VERSION ""

NS_ :

BS_:

BU_: Lenkmotor NJX Third_Party VCU IVT_Mod

BO_ 3221225472 VECTOR__INDEPENDENT_SIG_MSG: 0 Vector__XXX
 SG_ DMI_sdc_in_active : 0|1@1+ (1,0) [0|1] "" Vector__XXX
 SG_ DMI_sdc_out_active : 0|1@1+ (1,0) [0|1] "" Vector__XXX
 SG_ AMS_error_eio1 : 0|1@1+ (1,0) [0|1] "" Vector__XXX
 SG_ AMS_error_eio2 : 0|1@1+ (1,0) [0|1] "" Vector__XXX
 SG_ AMS_error_fan : 0|1@1+ (1,0) [0|1] "" Vector__XXX
 SG_ STW_rot_1 : 0|4@1+ (1,0) [0|15] "" Vector__XXX
 SG_ STW_rot_2 : 0|4@1+ (1,0) [0|15] "" Vector__XXX
 SG_ STW_btn_old_1 : 0|1@1+ (1,0) [0|1] "" Vector__XXX
 SG_ STW_btn_old_2 : 0|1@1+ (1,0) [0|1] "" Vector__XXX
 SG_ STW_btn_rr : 0|1@1+ (1,0) [0|1] "" Vector__XXX
 SG_ STW_btn_fr_l : 0|1@1+ (1,0) [0|1] "" Vector__XXX
 SG_ STW_btn_fl_l : 0|1@1+ (1,0) [0|1] "" Vector__XXX
 SG_ STW_btn_fl_r : 0|1@1+ (1,0) [0|1] "" Vector__XXX
 SG_ STW_btn_fr_r : 0|1@1+ (1,0) [0|1] "" Vector__XXX
 SG_ STW_btn_rl : 0|1@1+ (1,0) [0|1] "" Vector__XXX
 SG_ ISU_general_error : 0|1@1+ (1,0) [0|1] "" Vector__XXX
 SG_ ISU_mcu_error : 0|1@1+ (1,0) [0|1] "" Vector__XXX
 SG_ ISU_plaus_error : 0|1@1+ (1,0) [0|1] "" Vector__XXX
 SG_ ISU_realtime_error : 0|1@1+ (1,0) [0|1] "" Vector__XXX
 SG_ STW_CAN_Marker : 0|1@1+ (1,0) [0|1] "" Vector__XXX
 SG_ VCU_NM_all_active : 0|1@1+ (1,0) [0|1] "" Vector__XXX
 SG_ SCU_statusword : 0|16@1+ (1,0) [0|65535] "" Vector__XXX
 SG_ STW_general_error : 0|1@1+ (1,0) [0|1] "" Vector__XXX
 SG_ STW_mcu_error : 0|1@1+ (1,0) [0|1] "" Vector__XXX
 SG_ STW_plaus_error : 0|1@1+ (1,0) [0|1] "" Vector__XXX
 SG_ STW_realtime_error : 0|1@1+ (1,0) [0|1] "" Vector__XXX
 SG_ AMS_fan_pwm : 0|7@1+ (1,0) [0|127] "%" Vector__XXX
 SG_ AMS_i_battery : 0|16@1- (0.01,0) [-327.68|327.67] "A" Vector__XXX
 SG_ AMS_u_lv : 0|9@1+ (0.1,0) [0|51.1] "V" Vector__XXX
 SG_ AMS_temp_avg_stack_10 : 0|8@1+ (0.3,0) [0|76.5] "°C" Vector__XXX
 SG_ AMS_temp_avg_stack_11 : 0|8@1+ (0.3,0) [0|76.5] "°C" Vector__XXX
 SG_ AMS_temp_avg_stack_12 : 0|8@1+ (0.3,0) [0|76.5] "°C" Vector__XXX
 SG_ AMS_temp_avg_stack_9 : 0|8@1+ (0.3,0) [0|76.5] "°C" Vector__XXX
 SG_ AMS_temp_max_stack_10 : 0|8@1+ (0.3,0) [0|76.5] "°C" Vector__XXX
 SG_ AMS_temp_max_stack_11 : 0|8@1+ (0.3,0) [0|76.5] "°C" Vector__XXX
 SG_ AMS_temp_max_stack_12 : 0|8@1+ (0.3,0) [0|76.5] "°C" Vector__XXX
 SG_ AMS_temp_max_stack_9 : 0|8@1+ (0.3,0) [0|76.5] "°C" Vector__XXX
 SG_ VCU_GNSS_v_x : 0|32@1- (1,0) [-3.39999995214436E+38|3.39999995214436E+38] "m/s" Vector__XXX
 SG_ VCU_GNSS_v_y : 0|32@1- (1,0) [0|0] "m/s" Vector__XXX
 SG_ VCU_GNSS_error : 0|1@1+ (1,0) [0|1] "" Vector__XXX
 SG_ VCU_GNSS_fix : 0|1@1+ (1,0) [0|1] "" Vector__XXX
 SG_ VCU_GNSS_state : 0|2@1+ (1,0) [0|3] "" Vector__XXX
 SG_ VCU_GNSS_v_z : 0|32@1- (1,0) [0|0] "m/s" Vector__XXX
 SG_ VCU_IMU_error : 0|1@1+ (1,0) [0|1] "" Vector__XXX
 SG_ DMI_AMS_Fan_Conrtol : 0|7@1+ (1,0) [0|127] "" Vector__XXX
 SG_ SCU_steering_position : 0|32@1- (1,0) [-2147483648|2147483647] "" Vector__XXX
 SG_ NJX_CAN1_scu_ctrl_word : 0|16@1+ (1,0) [0|65535] "" Vector__XXX
 SG_ NJX_CAN1_scu_target_pos : 0|32@1- (1,0) [-2147483648|2147483647] "" Vector__XXX
 SG_ VCU_main_git_hash : 0|64@1- (1,0) [-9.22337203685478E+18|9.22337203685478E+18] "" Vector__XXX
 SG_ VCU_lib_git_hash : 0|64@1- (1,0) [-9.22337203685478E+18|9.22337203685478E+18] "" Vector__XXX

BO_ 52 SMU_BTN_sdc_reset_btn: 1 Third_Party
 SG_ SMU_BTN_rst_bt_pressed : 0|1@1+ (1,0) [0|1] "" Vector__XXX

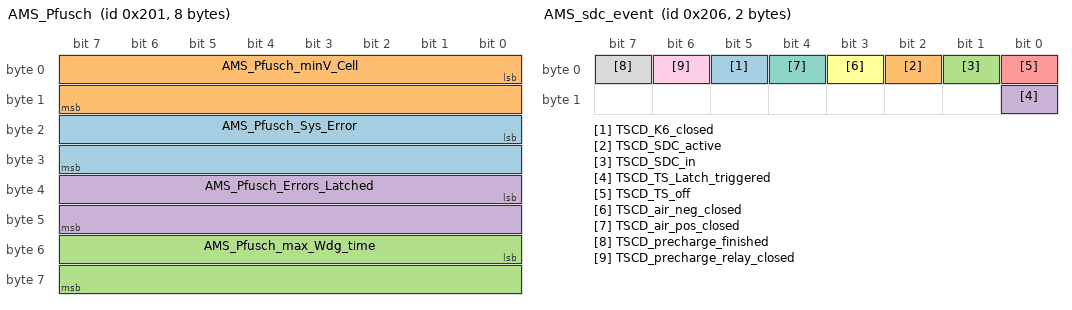
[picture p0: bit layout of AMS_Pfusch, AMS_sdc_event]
BO_ 513 AMS_Pfusch: 8 Vector__XXX
 SG_ AMS_Pfusch_Sys_Error : 16|16@1+ (1,0) [0|65535] "" Vector__XXX
 SG_ AMS_Pfusch_minV_Cell : 0|16@1+ (0.0001,0) [0|6.5535] "V" Vector__XXX
 SG_ AMS_Pfusch_max_Wdg_time : 48|16@1+ (0.001,0) [0|65.535] "s" Vector__XXX
 SG_ AMS_Pfusch_Errors_Latched : 32|16@1+ (1,0) [0|65535] "" Vector__XXX

BO_ 793 SMU_F_ASMS_state: 1 Third_Party
 SG_ SMU_F_ASMS_on : 0|1@1+ (1,0) [0|1] ""  VCU

BO_ 0 VCU_CAN1_nmt_node_control: 2 VCU
 SG_ VCU_CAN1_nmt_node_control : 0|16@1- (1,0) [0|0] ""  Third_Party

BO_ 1 CANopen_reserved_failsafe: 8 Third_Party

BO_ 48 DMI_tsa_btn: 1 Third_Party
 SG_ DMI_tsa_btn_pressed : 0|1@1+ (1,0) [0|1] ""  VCU

BO_ 50 DMI_r2d_btn: 1 Third_Party
 SG_ DMI_r2d_btn_pressed : 0|1@1+ (1,0) [0|1] ""  VCU

BO_ 518 AMS_sdc_event: 2 Third_Party
 SG_ TSCD_K6_closed : 5|1@1+ (1,0) [0|1] ""  VCU
 SG_ TSCD_SDC_active : 2|1@1+ (1,0) [0|1] ""  VCU
 SG_ TSCD_SDC_in : 1|1@1+ (1,0) [0|1] ""  VCU
 SG_ TSCD_TS_Latch_triggered : 8|1@1+ (1,0) [0|1] ""  VCU
 SG_ TSCD_TS_off : 0|1@1+ (1,0) [0|1] ""  VCU
 SG_ TSCD_air_neg_closed : 3|1@1+ (1,0) [0|1] ""  VCU
 SG_ TSCD_air_pos_closed : 4|1@1+ (1,0) [0|1] ""  VCU
 SG_ TSCD_precharge_finished : 7|1@1+ (1,0) [0|1] ""  VCU
 SG_ TSCD_precharge_relay_closed : 6|1@1+ (1,0) [0|1] ""  VCU

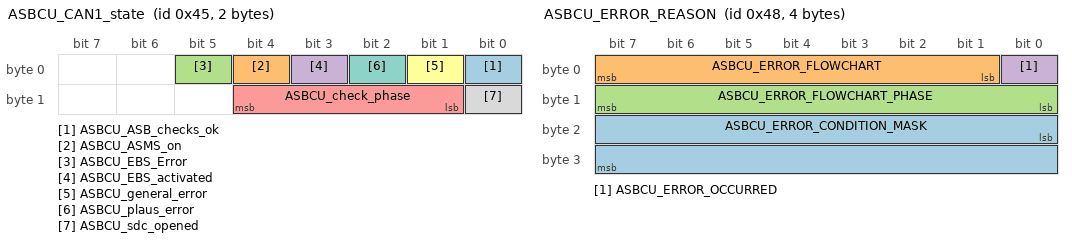
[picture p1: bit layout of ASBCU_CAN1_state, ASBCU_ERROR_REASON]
BO_ 69 ASBCU_CAN1_state: 2 Third_Party
 SG_ ASBCU_ASB_checks_ok : 0|1@1+ (1,0) [0|1] ""  VCU
 SG_ ASBCU_ASMS_on : 4|1@1+ (1,0) [0|1] ""  VCU
 SG_ ASBCU_EBS_Error : 5|1@1+ (1,0) [0|1] ""  VCU
 SG_ ASBCU_EBS_activated : 3|1@1+ (1,0) [0|1] ""  VCU
 SG_ ASBCU_check_phase : 9|4@1+ (1,0) [0|15] ""  VCU
 SG_ ASBCU_general_error : 1|1@1+ (1,0) [0|1] ""  VCU
 SG_ ASBCU_plaus_error : 2|1@1+ (1,0) [0|1] ""  VCU
 SG_ ASBCU_sdc_opened : 8|1@1+ (1,0) [0|1] ""  VCU

BO_ 70 ASBCU_CAN1_data: 2 Third_Party
 SG_ ASBCU_activated_sensor : 0|8@1+ (0.1,0) [0|25.5] ""  VCU
 SG_ ASBCU_armed_sensor : 8|8@1+ (0.1,0) [0|25.5] ""  VCU

BO_ 71 VCU_CAN1_ASBCU_Info: 8 VCU
 SG_ VCU_NJX_Mission_Status : 0|3@1+ (1,0) [0|7] ""  Third_Party

BO_ 72 ASBCU_ERROR_REASON: 4 Third_Party
 SG_ ASBCU_ERROR_CONDITION_MASK : 16|16@1+ (1,0) [0|1] ""  VCU
 SG_ ASBCU_ERROR_FLOWCHART : 1|7@1+ (1,0) [0|1] ""  VCU
 SG_ ASBCU_ERROR_FLOWCHART_PHASE : 8|8@1+ (1,0) [0|1] ""  VCU
 SG_ ASBCU_ERROR_OCCURRED : 0|1@1+ (1,0) [0|1] ""  VCU

BO_ 512 AMS_state: 6 Third_Party
 SG_ AMS_error_batt_cv_ct_init : 6|1@1+ (1,0) [0|1] ""  VCU
 SG_ AMS_error_batt_iso_meas : 4|1@1+ (1,0) [0|1] ""  VCU
 SG_ AMS_error_batt_iso_meas_monitor : 5|1@1+ (1,0) [0|1] ""  VCU
 SG_ AMS_error_batt_vit_init : 3|1@1+ (1,0) [0|1] ""  VCU
 SG_ AMS_error_bms_init_1 : 8|1@1+ (1,0) [0|1] ""  VCU
 SG_ AMS_error_bms_init_2 : 9|1@1+ (1,0) [0|1] ""  VCU
 SG_ AMS_error_bms_init_3 : 10|1@1+ (1,0) [0|1] ""  VCU
 SG_ AMS_error_can_init : 13|1@1+ (1,0) [0|1] ""  VCU
 SG_ AMS_error_current_init : 15|1@1+ (1,0) [0|1] ""  VCU
 SG_ AMS_error_cv_ct_rx_monitor : 7|1@1+ (1,0) [0|1] ""  VCU
 SG_ AMS_error_eeprom_rd : 11|1@1+ (1,0) [0|1] ""  VCU
 SG_ AMS_error_eeprom_wr : 12|1@1+ (1,0) [0|1] ""  VCU
 SG_ AMS_error_lim_cell_minmax_volt : 17|1@1+ (1,0) [0|1] ""  VCU
 SG_ AMS_error_lim_current_1_cont : 19|1@1+ (1,0) [0|1] ""  VCU
 SG_ AMS_error_lim_current_1_max : 20|1@1+ (1,0) [0|1] ""  VCU
 SG_ AMS_error_lim_current_1_pulse : 18|1@1+ (1,0) [0|1] ""  VCU
 SG_ AMS_error_lim_current_2_cont : 21|1@1+ (1,0) [0|1] ""  VCU
 SG_ AMS_error_lim_iso : 22|1@1+ (1,0) [0|1] ""  VCU
 SG_ AMS_error_lim_soc : 23|1@1+ (1,0) [0|1] ""  VCU
 SG_ AMS_error_lim_temp : 24|1@1+ (1,0) [0|1] ""  VCU
 SG_ AMS_error_lim_volt : 16|1@1+ (1,0) [0|1] ""  VCU
 SG_ AMS_error_lim_volt_ext : 25|1@1+ (1,0) [0|1] ""  VCU
 SG_ AMS_error_not_ready : 14|1@1+ (1,0) [0|1] ""  VCU
 SG_ AMS_general_error : 26|1@1+ (1,0) [0|1] ""  VCU
 SG_ AMS_mcu_error : 27|1@1+ (1,0) [0|1] ""  VCU
 SG_ AMS_plaus_error : 28|1@1+ (1,0) [0|1] ""  VCU
 SG_ AMS_realtime_error : 29|1@1+ (1,0) [0|1] ""  VCU
 SG_ AMS_soc : 32|16@1+ (0.1,0) [0|6553.5] "%"  VCU

BO_ 88 VCU_CAN1_ASI_state: 1 VCU
 SG_ ASI_Status : 0|8@1+ (1,0) [0|255] ""  Third_Party

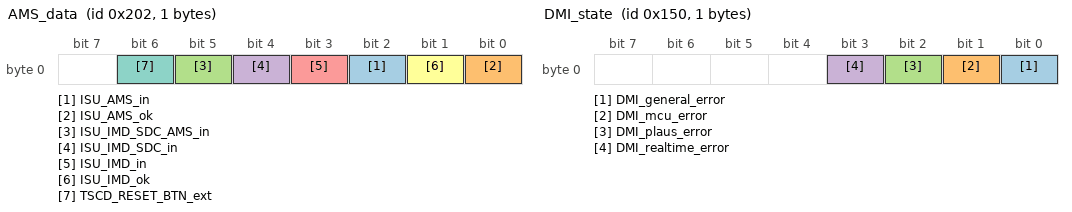
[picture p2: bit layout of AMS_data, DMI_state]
BO_ 514 AMS_data: 1 Third_Party
 SG_ ISU_AMS_in : 2|1@1+ (1,0) [0|0] ""  VCU
 SG_ ISU_AMS_ok : 0|1@1+ (1,0) [0|0] ""  VCU
 SG_ ISU_IMD_SDC_AMS_in : 5|1@1+ (1,0) [0|0] ""  VCU
 SG_ ISU_IMD_SDC_in : 4|1@1+ (1,0) [0|0] ""  VCU
 SG_ ISU_IMD_in : 3|1@1+ (1,0) [0|0] ""  VCU
 SG_ ISU_IMD_ok : 1|1@1+ (1,0) [0|0] ""  VCU
 SG_ TSCD_RESET_BTN_ext : 6|1@1+ (1,0) [0|1] ""  VCU

BO_ 127 CANopen_reserved_active: 8 Third_Party

BO_ 128 CANopen_reserved_sync: 8 Third_Party

BO_ 146 STR_emergency: 8 Third_Party
 SG_ STR_error_code : 0|16@1+ (1,0) [0|0] ""  VCU
 SG_ STR_error_register : 16|8@1+ (1,0) [0|0] ""  VCU

BO_ 322 VCU_CAN1_vehicle_state: 7 VCU
 SG_ AMS_general_error : 16|1@1+ (1,0) [0|1] ""  Third_Party
 SG_ VCU_FS_Logger_Status : 13|1@1+ (1,0) [0|1] ""  Third_Party
 SG_ VCU_LC_state : 20|2@1+ (1,0) [0|3] ""  Third_Party
 SG_ VCU_RES_status : 17|3@1+ (1,0) [0|7] ""  Third_Party
 SG_ VCU_VelEstMode : 10|2@1+ (1,0) [0|3] ""  Third_Party
 SG_ VCU_apps_error : 0|1@1+ (1,0) [0|1] ""  Third_Party
 SG_ VCU_bl_active : 14|1@1+ (1,0) [0|1] ""  Third_Party
 SG_ VCU_bpps_error : 1|1@1+ (1,0) [0|1] ""  Third_Party
 SG_ VCU_bps_error : 2|1@1+ (1,0) [0|1] ""  Third_Party
 SG_ VCU_fan_l_error : 22|1@1+ (1,0) [0|1] ""  Third_Party
 SG_ VCU_fan_r_error : 23|1@1+ (1,0) [0|1] ""  Third_Party
 SG_ VCU_fan_rl_speed : 36|6@1+ (1.5873016,0) [0|100.0000008] "%"  Third_Party
 SG_ VCU_fan_rr_speed : 42|6@1+ (1.5873016,0) [0|100.0000008] ""  Third_Party
 SG_ VCU_pump_l_error : 8|1@1+ (1,0) [0|1] ""  Third_Party
 SG_ VCU_pump_r_error : 9|1@1+ (1,0) [0|1] ""  Third_Party
 SG_ VCU_pump_rl_speed : 24|6@1+ (1.5873016,0) [0|100.0000008] ""  Third_Party
 SG_ VCU_pump_rr_speed : 30|6@1+ (1.5873016,0) [0|49.2063496] ""  Third_Party
 SG_ VCU_ready_for_rtd : 7|1@1+ (1,0) [0|1] ""  Third_Party
 SG_ VCU_ready_for_tsa : 6|1@1+ (1,0) [0|1] ""  Third_Party
 SG_ VCU_rtd : 5|1@1+ (1,0) [0|1] ""  Third_Party
 SG_ VCU_rtds_active : 15|1@1+ (1,0) [0|1] ""  Third_Party
 SG_ VCU_torque_alloc_error : 12|1@1+ (1,0) [0|1] ""  Third_Party
 SG_ VCU_tsa : 4|1@1+ (1,0) [0|1] ""  Third_Party
 SG_ VCU_vehicle_error : 3|1@1+ (1,0) [0|1] ""  Third_Party

BO_ 336 DMI_state: 1 Third_Party
 SG_ DMI_general_error : 0|1@1+ (1,0) [0|1] ""  VCU
 SG_ DMI_mcu_error : 1|1@1+ (1,0) [0|1] ""  VCU
 SG_ DMI_plaus_error : 2|1@1+ (1,0) [0|1] ""  VCU
 SG_ DMI_realtime_error : 3|1@1+ (1,0) [0|1] ""  VCU

BO_ 338 GL2010_CAN1_state: 4 Third_Party
 SG_ GL201_CAN1_dummy : 0|32@1- (1,0) [-2147483648|2147483647] ""  VCU

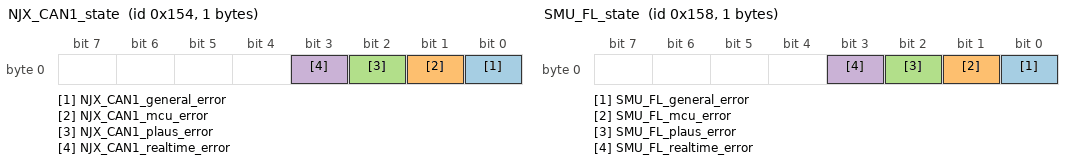
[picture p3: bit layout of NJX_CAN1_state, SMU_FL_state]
BO_ 340 NJX_CAN1_state: 1 NJX
 SG_ NJX_CAN1_general_error : 0|1@1+ (1,0) [0|1] ""  VCU
 SG_ NJX_CAN1_mcu_error : 1|1@1+ (1,0) [0|1] ""  VCU
 SG_ NJX_CAN1_plaus_error : 2|1@1+ (1,0) [0|1] ""  VCU
 SG_ NJX_CAN1_realtime_error : 3|1@1+ (1,0) [0|1] ""  VCU

BO_ 344 SMU_FL_state: 1 Third_Party
 SG_ SMU_FL_general_error : 0|1@1+ (1,0) [0|1] ""  VCU
 SG_ SMU_FL_mcu_error : 1|1@1+ (1,0) [0|1] ""  VCU
 SG_ SMU_FL_plaus_error : 2|1@1+ (1,0) [0|1] ""  VCU
 SG_ SMU_FL_realtime_error : 3|1@1+ (1,0) [0|1] ""  VCU

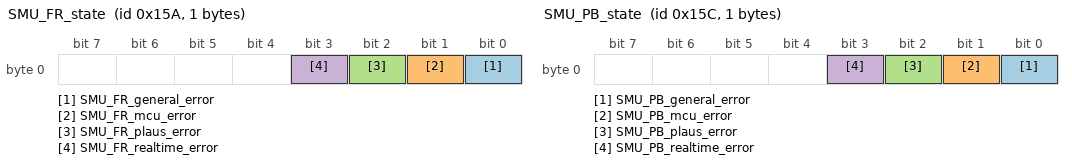
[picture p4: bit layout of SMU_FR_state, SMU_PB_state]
BO_ 346 SMU_FR_state: 1 Third_Party
 SG_ SMU_FR_general_error : 0|1@1+ (1,0) [0|1] ""  VCU
 SG_ SMU_FR_mcu_error : 1|1@1+ (1,0) [0|1] ""  VCU
 SG_ SMU_FR_plaus_error : 2|1@1+ (1,0) [0|1] ""  VCU
 SG_ SMU_FR_realtime_error : 3|1@1+ (1,0) [0|1] ""  VCU

BO_ 348 SMU_PB_state: 1 Third_Party
 SG_ SMU_PB_general_error : 0|1@1+ (1,0) [0|1] ""  VCU
 SG_ SMU_PB_mcu_error : 1|1@1+ (1,0) [0|1] ""  VCU
 SG_ SMU_PB_plaus_error : 2|1@1+ (1,0) [0|1] ""  VCU
 SG_ SMU_PB_realtime_error : 3|1@1+ (1,0) [0|1] ""  VCU

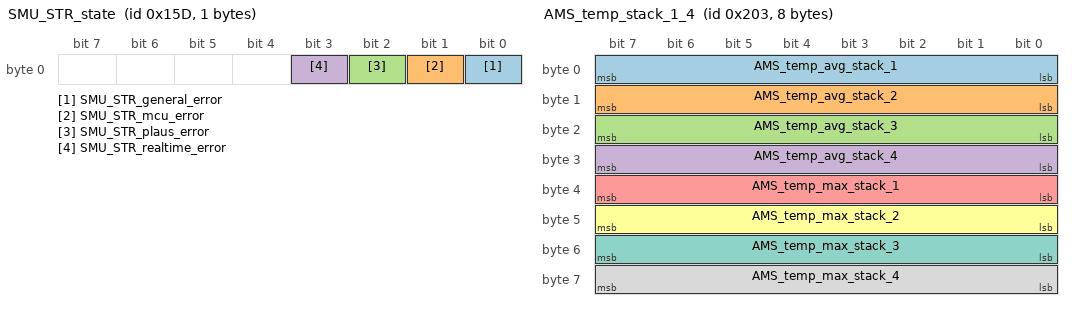
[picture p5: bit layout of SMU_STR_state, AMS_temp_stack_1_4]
BO_ 349 SMU_STR_state: 1 Third_Party
 SG_ SMU_STR_general_error : 0|1@1+ (1,0) [0|1] ""  VCU
 SG_ SMU_STR_mcu_error : 1|1@1+ (1,0) [0|1] ""  VCU
 SG_ SMU_STR_plaus_error : 2|1@1+ (1,0) [0|1] ""  VCU
 SG_ SMU_STR_realtime_error : 3|1@1+ (1,0) [0|1] ""  VCU

BO_ 352 VCU_CAN1_state: 6 VCU
 SG_ VCU_CAN1_general_error : 0|1@1+ (1,0) [0|1] ""  Third_Party
 SG_ VCU_CAN1_plaus_error : 2|1@1+ (1,0) [0|1] ""  Third_Party
 SG_ VCU_CAN1_realtime_error : 3|1@1+ (1,0) [0|1] ""  Third_Party
 SG_ VCU_diag_state : 16|8@1+ (1,0) [0|255] ""  Third_Party
 SG_ VCU_diag_state_error : 24|8@1+ (1,0) [0|255] ""  Third_Party
 SG_ VCU_ecu_error_ams : 4|1@1+ (1,0) [0|1] ""  Third_Party
 SG_ VCU_ecu_error_dmi : 5|1@1+ (1,0) [0|1] ""  Third_Party
 SG_ VCU_ecu_error_inv_f : 6|1@1+ (1,0) [0|1] ""  Third_Party
 SG_ VCU_ecu_error_inv_r : 7|1@1+ (1,0) [0|1] ""  Third_Party
 SG_ VCU_ecu_error_isu : 1|1@1+ (1,0) [0|1] ""  Third_Party
 SG_ VCU_ecu_error_scu : 8|1@1+ (1,0) [0|1] ""  Third_Party
 SG_ VCU_ecu_error_smu_btn : 9|1@1+ (1,0) [0|1] ""  Third_Party
 SG_ VCU_ecu_error_smu_fl : 10|1@1+ (1,0) [0|1] ""  Third_Party
 SG_ VCU_ecu_error_smu_fr : 11|1@1+ (1,0) [0|1] ""  Third_Party
 SG_ VCU_ecu_error_smu_pb : 12|1@1+ (1,0) [0|1] ""  Third_Party
 SG_ VCU_ecu_error_smu_rl : 13|1@1+ (1,0) [0|1] ""  Third_Party
 SG_ VCU_ecu_error_smu_rr : 14|1@1+ (1,0) [0|1] ""  Third_Party
 SG_ VCU_ecu_error_tscd : 15|1@1+ (1,0) [0|1] ""  Third_Party
 SG_ VCU_exec_time : 40|8@1+ (0.025,0) [0|6.375] "ms"  Third_Party
 SG_ VCU_watchdog_state : 32|8@1+ (1,0) [0|255] ""  Third_Party

BO_ 515 AMS_temp_stack_1_4: 8 Third_Party
 SG_ AMS_temp_avg_stack_1 : 0|8@1+ (0.3,0) [0|76.5] "°C"  VCU
 SG_ AMS_temp_avg_stack_2 : 8|8@1+ (0.3,0) [0|76.5] "°C"  VCU
 SG_ AMS_temp_avg_stack_3 : 16|8@1+ (0.3,0) [0|76.5] "°C"  VCU
 SG_ AMS_temp_avg_stack_4 : 24|8@1+ (0.3,0) [0|76.5] "°C"  VCU
 SG_ AMS_temp_max_stack_1 : 32|8@1+ (0.3,0) [0|76.5] "°C"  VCU
 SG_ AMS_temp_max_stack_2 : 40|8@1+ (0.3,0) [0|76.5] "°C"  VCU
 SG_ AMS_temp_max_stack_3 : 48|8@1+ (0.3,0) [0|76.5] "°C"  VCU
 SG_ AMS_temp_max_stack_4 : 56|8@1+ (0.3,0) [0|76.5] "°C"  VCU

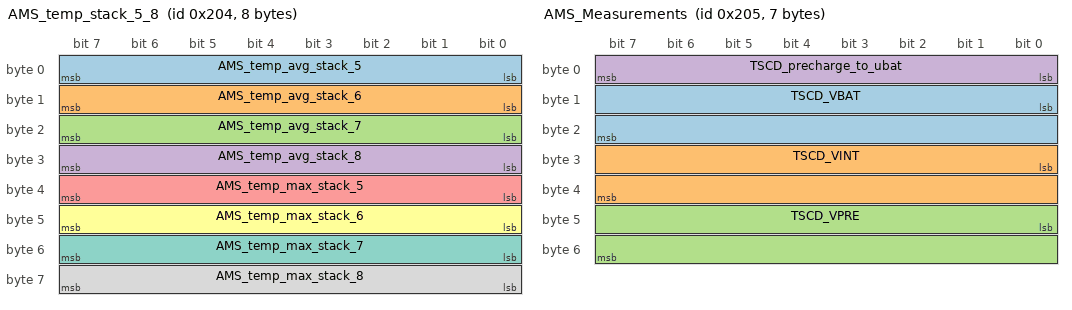
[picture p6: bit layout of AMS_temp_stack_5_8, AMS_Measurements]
BO_ 516 AMS_temp_stack_5_8: 8 Third_Party
 SG_ AMS_temp_avg_stack_5 : 0|8@1+ (0.3,0) [0|76.5] "°C"  VCU
 SG_ AMS_temp_avg_stack_6 : 8|8@1+ (0.3,0) [0|76.5] "°C"  VCU
 SG_ AMS_temp_avg_stack_7 : 16|8@1+ (0.3,0) [0|76.5] "°C"  VCU
 SG_ AMS_temp_avg_stack_8 : 24|8@1+ (0.3,0) [0|76.5] "°C"  VCU
 SG_ AMS_temp_max_stack_5 : 32|8@1+ (0.3,0) [0|76.5] "°C"  VCU
 SG_ AMS_temp_max_stack_6 : 40|8@1+ (0.3,0) [0|76.5] "°C"  VCU
 SG_ AMS_temp_max_stack_7 : 48|8@1+ (0.3,0) [0|76.5] "°C"  VCU
 SG_ AMS_temp_max_stack_8 : 56|8@1+ (0.3,0) [0|76.5] "°C"  VCU

BO_ 517 AMS_Measurements: 7 Third_Party
 SG_ TSCD_VBAT : 8|16@1+ (0.01,0) [0|655.35] "V"  VCU
 SG_ TSCD_VINT : 24|16@1+ (0.01,0) [0|655.35] "V"  VCU
 SG_ TSCD_VPRE : 40|16@1+ (0.01,0) [0|655.35] "V"  VCU
 SG_ TSCD_precharge_to_ubat : 0|8@1+ (1,0) [0|255] "%"  VCU

BO_ 530 VCU_RL_data: 2 VCU
 SG_ VCU_RL_gear_temp : 0|8@1+ (0.5,0) [0|127.5] "C"  Third_Party
 SG_ VCU_RL_motor_temp : 8|8@1+ (0.5,0) [0|127.5] "C"  Third_Party

BO_ 534 VCU_RR_data: 2 VCU
 SG_ VCU_RR_gear_temp : 0|8@1+ (0.5,0) [0|127.5] "C"  Third_Party
 SG_ VCU_RR_motor_temp : 8|8@1+ (0.5,0) [0|0] "C"  Third_Party

BO_ 600 VCU_CAN1_IMU_x: 8 VCU
 SG_ VCU_IMU_acc_x : 0|32@1- (1,0) [-3.39999995214436E+38|3.39999995214436E+38] "m/s^2"  Third_Party
 SG_ VCU_IMU_ang_x : 32|32@1- (1,0) [-3.39999995214436E+38|3.39999995214436E+38] "rad/s"  Third_Party

BO_ 601 VCU_CAN1_IMU_y: 8 VCU
 SG_ VCU_IMU_acc_y : 0|32@1- (1,0) [0|0] "m/s^2"  Third_Party
 SG_ VCU_IMU_ang_y : 32|32@1- (1,0) [0|0] "rad/s"  Third_Party

BO_ 602 VCU_CAN1_IMU_z: 8 VCU
 SG_ VCU_IMU_acc_z : 0|32@1- (1,0) [-3.39999995214436E+38|3.39999995214436E+38] "m/s^2"  Third_Party
 SG_ VCU_IMU_ang_z : 32|32@1- (1,0) [-3.39999995214436E+38|3.39999995214436E+38] "rad/s"  Third_Party

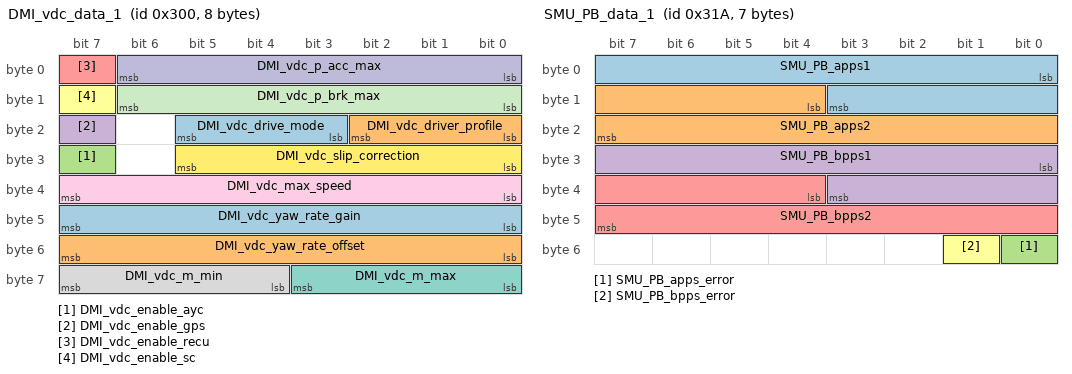
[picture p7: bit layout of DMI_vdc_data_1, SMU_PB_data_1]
BO_ 768 DMI_vdc_data_1: 8 Third_Party
 SG_ DMI_vdc_drive_mode : 19|3@1+ (1,0) [0|7] ""  VCU
 SG_ DMI_vdc_driver_profile : 16|3@1+ (1,0) [0|7] ""  VCU
 SG_ DMI_vdc_enable_ayc : 31|1@1+ (1,0) [0|1] ""  VCU
 SG_ DMI_vdc_enable_gps : 23|1@1+ (1,0) [0|1] ""  VCU
 SG_ DMI_vdc_enable_recu : 7|1@1+ (1,0) [0|1] ""  VCU
 SG_ DMI_vdc_enable_sc : 15|1@1+ (1,0) [0|1] ""  VCU
 SG_ DMI_vdc_m_max : 56|4@1+ (2.5,0) [0|37.5] "Nm"  VCU
 SG_ DMI_vdc_m_min : 60|4@1+ (2.5,-37.5) [-37.5|0] "Nm"  VCU
 SG_ DMI_vdc_max_speed : 32|8@1+ (100,0) [0|25500] "1/min"  VCU
 SG_ DMI_vdc_p_acc_max : 0|7@1+ (1000,0) [0|127000] "W"  VCU
 SG_ DMI_vdc_p_brk_max : 8|7@1+ (1000,5) [5|127005] "W"  VCU
 SG_ DMI_vdc_slip_correction : 24|6@1- (0.01,0) [-0.32|0.31] ""  VCU
 SG_ DMI_vdc_yaw_rate_gain : 40|8@1+ (0.005,0.3625) [0.3625|1.6375] ""  VCU
 SG_ DMI_vdc_yaw_rate_offset : 48|8@1- (0.005,0) [-0.64|0.635] "rad/s"  VCU

BO_ 769 DMI_vdc_data_2: 8 Third_Party
 SG_ DMI_vdc2_AMI : 0|3@1+ (1,0) [0|7] ""  VCU

BO_ 786 SMU_FL_data_1: 2 Third_Party
 SG_ SMU_FL_suspension_travel : 0|16@1- (0.01,0) [-327.68|327.67] "mm"  VCU

BO_ 788 SMU_FL_data_2: 2 Third_Party
 SG_ SMU_FL_gear_temp : 0|8@1+ (0.5,0) [0|127.5] "ï¿½C"  VCU
 SG_ SMU_FL_motor_temp : 8|8@1+ (0.5,0) [0|127.5] "ï¿½C"  VCU

BO_ 789 SMU_FL_data_3: 2 Third_Party
 SG_ SMU_FL_wheelspeed : 0|16@1- (0.1,0) [-3276.8|3276.7] "U/min"  VCU

BO_ 790 SMU_FR_data_1: 2 Third_Party
 SG_ SMU_FR_suspension_travel : 0|16@1- (0.01,0) [-327.68|327.67] "mm"  VCU

BO_ 791 SMU_FR_data_3: 2 Third_Party
 SG_ SMU_FR_wheelspeed : 0|16@1- (0.1,0) [-3276.8|3276.7] "U/min"  VCU

BO_ 792 SMU_FR_data_2: 2 Third_Party
 SG_ SMU_FR_gear_temp : 0|8@1+ (0.5,0) [0|127.5] "ï¿½C"  VCU
 SG_ SMU_FR_motor_temp : 8|8@1+ (0.5,0) [0|127.5] "ï¿½C"  VCU

BO_ 794 SMU_PB_data_1: 7 Third_Party
 SG_ SMU_PB_apps1 : 0|12@1+ (0.025,0) [0|102.375] "%"  VCU
 SG_ SMU_PB_apps2 : 12|12@1+ (0.025,0) [0|102.375] "%"  VCU
 SG_ SMU_PB_apps_error : 48|1@1+ (1,0) [0|1] ""  VCU
 SG_ SMU_PB_bpps1 : 24|12@1+ (0.025,0) [0|102.375] "%"  VCU
 SG_ SMU_PB_bpps2 : 36|12@1+ (0.025,0) [0|102.375] "%"  VCU
 SG_ SMU_PB_bpps_error : 49|1@1+ (1,0) [0|1] ""  VCU

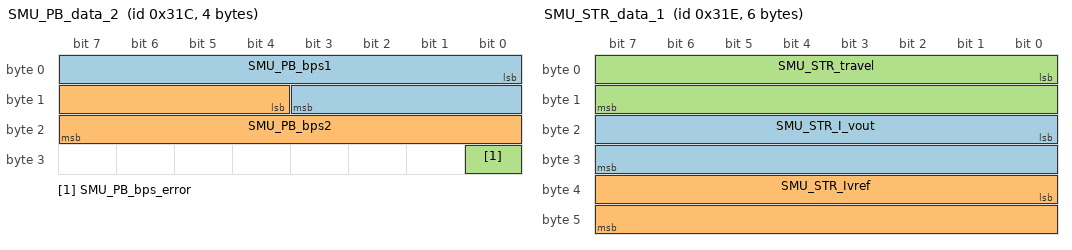
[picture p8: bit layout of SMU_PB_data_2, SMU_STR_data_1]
BO_ 796 SMU_PB_data_2: 4 Third_Party
 SG_ SMU_PB_bps1 : 0|12@1+ (0.1,0) [0|409.5] "bar"  VCU
 SG_ SMU_PB_bps2 : 12|12@1+ (0.1,0) [0|409.5] "bar"  VCU
 SG_ SMU_PB_bps_error : 24|1@1+ (1,0) [0|1] ""  VCU

BO_ 798 SMU_STR_data_1: 6 Third_Party
 SG_ SMU_STR_I_vout : 16|16@1- (0.1,0) [-3276.8|3276.7] ""  VCU
 SG_ SMU_STR_Ivref : 32|16@1- (0.1,0) [-3276.8|3276.7] ""  VCU
 SG_ SMU_STR_travel : 0|16@1- (0.01,0) [-327.68|327.67] "mm"  VCU

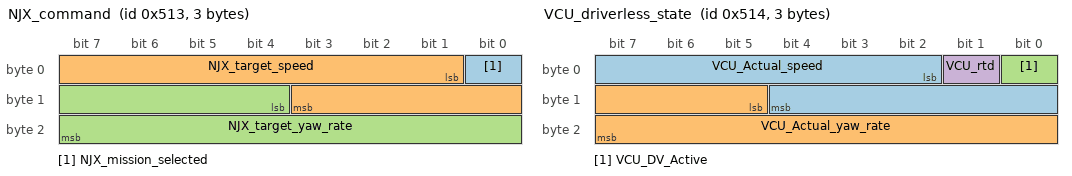
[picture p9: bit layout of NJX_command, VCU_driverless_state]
BO_ 1299 NJX_command: 3 NJX
 SG_ NJX_mission_selected : 0|1@1+ (1,0) [0|1] ""  VCU
 SG_ NJX_target_speed : 1|11@1+ (0.02,0) [0|40.94] "m/s"  VCU
 SG_ NJX_target_yaw_rate : 12|12@1- (0.002,0) [-4.096|4.094] "rad/s"  VCU

BO_ 1300 VCU_driverless_state: 3 VCU
 SG_ VCU_Actual_speed : 2|11@1+ (0.02,0) [0|40.94] "m/s"  NJX
 SG_ VCU_Actual_yaw_rate : 13|11@1- (0.004,0) [-4.096|4.092] "rad/s"  NJX
 SG_ VCU_DV_Active : 0|1@1+ (1,0) [0|1] ""  NJX
 SG_ VCU_rtd : 1|1@1+ (1,0) [0|1] ""  NJX

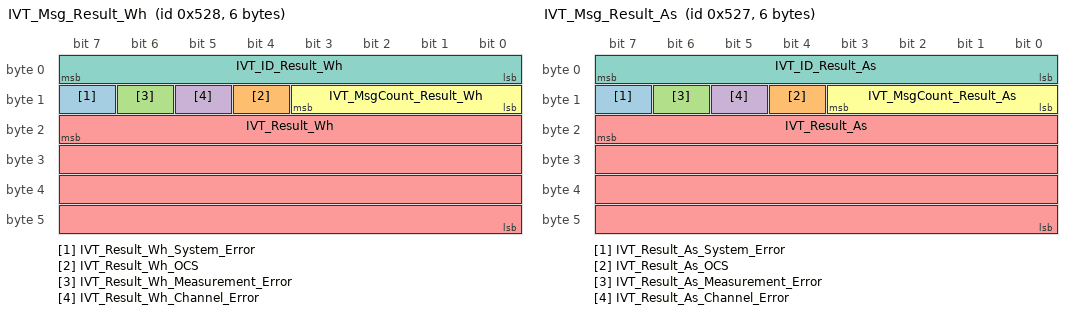
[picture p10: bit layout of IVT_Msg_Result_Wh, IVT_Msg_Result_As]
BO_ 1320 IVT_Msg_Result_Wh: 6 IVT_Mod
 SG_ IVT_Result_Wh_System_Error : 15|1@0+ (1,0) [0|0] ""  VCU
 SG_ IVT_Result_Wh_OCS : 12|1@0+ (1,0) [0|0] ""  VCU
 SG_ IVT_Result_Wh_Measurement_Error : 14|1@0+ (1,0) [0|0] ""  VCU
 SG_ IVT_Result_Wh_Channel_Error : 13|1@0+ (1,0) [0|0] ""  VCU
 SG_ IVT_Result_Wh : 23|32@0- (1,0) [-2147483648|2147483647] "Wh"  VCU
 SG_ IVT_MsgCount_Result_Wh : 11|4@0+ (1,0) [0|0] ""  VCU
 SG_ IVT_ID_Result_Wh : 7|8@0+ (1,0) [7|7] ""  VCU

BO_ 1319 IVT_Msg_Result_As: 6 IVT_Mod
 SG_ IVT_Result_As_System_Error : 15|1@0+ (1,0) [0|0] ""  VCU
 SG_ IVT_Result_As_OCS : 12|1@0+ (1,0) [0|0] ""  VCU
 SG_ IVT_Result_As_Measurement_Error : 14|1@0+ (1,0) [0|0] ""  VCU
 SG_ IVT_Result_As_Channel_Error : 13|1@0+ (1,0) [0|0] ""  VCU
 SG_ IVT_Result_As : 23|32@0- (1,0) [-21474836478|2147483647] "As"  VCU
 SG_ IVT_MsgCount_Result_As : 11|4@0+ (1,0) [0|0] ""  VCU
 SG_ IVT_ID_Result_As : 7|8@0+ (1,0) [6|6] ""  VCU

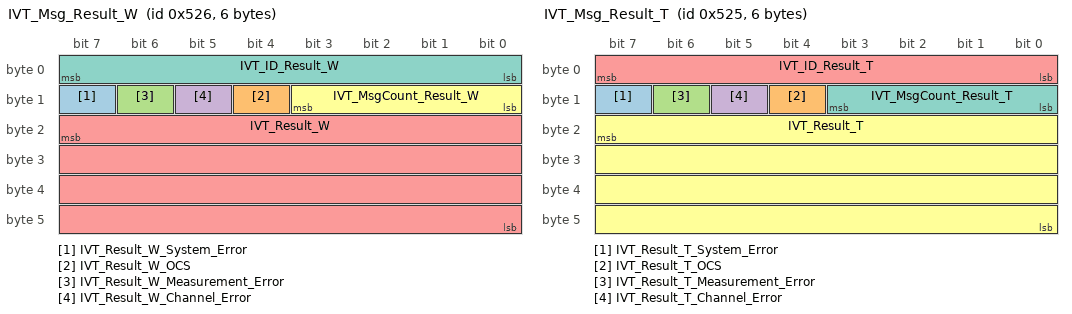
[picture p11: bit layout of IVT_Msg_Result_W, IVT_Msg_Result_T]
BO_ 1318 IVT_Msg_Result_W: 6 IVT_Mod
 SG_ IVT_Result_W_System_Error : 15|1@0+ (1,0) [0|0] ""  VCU
 SG_ IVT_Result_W_OCS : 12|1@0+ (1,0) [0|0] ""  VCU
 SG_ IVT_Result_W_Measurement_Error : 14|1@0+ (1,0) [0|0] ""  VCU
 SG_ IVT_Result_W_Channel_Error : 13|1@0+ (1,0) [0|0] ""  VCU
 SG_ IVT_Result_W : 23|32@0- (1,0) [-2147483648|2147483647] "W"  VCU
 SG_ IVT_MsgCount_Result_W : 11|4@0+ (1,0) [0|0] ""  VCU
 SG_ IVT_ID_Result_W : 7|8@0+ (1,0) [5|5] ""  VCU

BO_ 1297 IVT_Msg_Response: 8 IVT_Mod
 SG_ _B1_Trigger_spare m177 : 15|8@0+ (1,0) [0|0] "" Vector__XXX
 SG_ _B1_07_Trigger_WH m177 : 23|1@0+ (1,0) [0|0] "" Vector__XXX
 SG_ _B1_06_Trigger_As m177 : 22|1@0+ (1,0) [0|0] "" Vector__XXX
 SG_ _B1_05_Trigger_W m177 : 21|1@0+ (1,0) [0|0] "" Vector__XXX
 SG_ _B1_04_Trigger_T m177 : 20|1@0+ (1,0) [0|0] "" Vector__XXX
 SG_ _B1_03_Trigger_U3 m177 : 19|1@0+ (1,0) [0|0] "" Vector__XXX
 SG_ _B1_02_Trigger_U2 m177 : 18|1@0+ (1,0) [0|0] "" Vector__XXX
 SG_ _B1_01_Trigger_U1 m177 : 17|1@0+ (1,0) [0|0] "" Vector__XXX
 SG_ _B1_00_Trigger_I m177 : 16|1@0+ (1,0) [0|0] "" Vector__XXX
 SG_ _B2_Resp_Store_Device_SN m178 : 23|32@0+ (1,0) [0|0] "" Vector__XXX
 SG_ _FF_Wrong_Command m255 : 15|8@0+ (1,0) [0|0] "" Vector__XXX
 SG_ _BF_Restart_Alive_SN m191 : 31|32@0+ (1,0) [0|0] "" Vector__XXX
 SG_ _BF_Restart_Alive_Cmd_ID m191 : 15|16@0+ (1,0) [0|0] "" Vector__XXX
 SG_ _BA_Resp_SW_Ver_Vear m186 : 39|8@0+ (1,0) [0|0] "" Vector__XXX
 SG_ _BA_Resp_SW_Ver_Revision m186 : 31|8@0+ (1,0) [0|0] "" Vector__XXX
 SG_ _BA_Resp_SW_Ver_Month m186 : 40|8@1- (1,0) [0|0] "" Vector__XXX
 SG_ _BA_Resp_SW_Ver_Minor m186 : 23|8@0+ (1,0) [0|0] "" Vector__XXX
 SG_ _BA_Resp_SW_Ver_Internal m186 : 63|8@0+ (1,0) [0|0] "" Vector__XXX
 SG_ _BA_Resp_SW_Ver_Day m186 : 55|8@0+ (1,0) [0|0] "" Vector__XXX
 SG_ _B9_Resp_Device_Com m185 : 47|8@0+ (1,0) [0|0] "" Vector__XXX
 SG_ _B9_Resp_Device_current m185 : 23|12@0+ (1,0) [0|0] "A" Vector__XXX
 SG_ _B9_Resp_Device_TOI m185 : 39|8@0+ (1,0) [0|0] "" Vector__XXX
 SG_ _B9_Resp_Device_V_supply m185 : 55|8@0+ (1,0) [0|0] "V" Vector__XXX
 SG_ _B9_Resp_Device_Voltage_chan m185 : 27|4@0+ (1,0) [0|0] "" Vector__XXX
 SG_ _80_Resp_MeasError_Item m128 : 15|8@0+ (1,0) [0|0] "" Vector__XXX
 SG_ _80_Resp_MeasError_Count_Mask m128 : 23|16@0+ (1,0) [0|0] "" Vector__XXX
 SG_ _81_Resp_SystemError_Item m129 : 15|8@0+ (1,0) [0|0] "" Vector__XXX
 SG_ _81_Resp_SystemError_Count_Mask m129 : 23|16@0+ (1,0) [0|0] "" Vector__XXX
 SG_ _82_Resp_AllLogData_Item m130 : 15|8@0+ (1,0) [0|0] "" Vector__XXX
 SG_ _82_Resp_AllLogData_Counter m130 : 23|48@0+ (1,0) [0|0] "" Vector__XXX
 SG_ _83_Resp_LogData_Item m131 : 15|8@0+ (1,0) [0|0] "" Vector__XXX
 SG_ _83_Resp_LogData_Counter m131 : 23|48@0+ (1,0) [0|0] "" Vector__XXX
 SG_ _90_Resp_Can_ID_SN_I m144 : 31|32@0+ (1,0) [0|0] "" Vector__XXX
 SG_ _90_Resp_Can_ID_val_I m144 : 15|16@0+ (1,0) [0|0] "" Vector__XXX
 SG_ _91_Resp_Can_ID_SN_U1 m145 : 31|32@0+ (1,0) [0|0] "" Vector__XXX
 SG_ _91_Resp_Can_ID_val_U1 m145 : 15|16@0+ (1,0) [0|0] "" Vector__XXX
 SG_ _92_Resp_Can_ID_SN_U2 m146 : 31|32@0+ (1,0) [0|0] "" Vector__XXX
 SG_ _92_Resp_Can_ID_val_U2 m146 : 15|16@0+ (1,0) [0|0] "" Vector__XXX
 SG_ _93_Resp_Can_ID_SN_U3 m147 : 31|32@0+ (1,0) [0|0] "" Vector__XXX
 SG_ _93_Resp_Can_ID_val_U3 m147 : 15|16@0+ (1,0) [0|0] "" Vector__XXX
 SG_ _94_Resp_Can_ID_SN_T m148 : 31|32@0+ (1,0) [0|0] "" Vector__XXX
 SG_ _94_Resp_Can_ID_val_T m148 : 15|16@0+ (1,0) [0|0] "" Vector__XXX
 SG_ _95_Resp_Can_ID_SN_W m149 : 31|32@0+ (1,0) [0|0] "" Vector__XXX
 SG_ _95_Resp_Can_ID_val_W m149 : 15|16@0+ (1,0) [0|0] "" Vector__XXX
 SG_ _96_Resp_Can_ID_SN_As m150 : 31|32@0+ (1,0) [0|0] "" Vector__XXX
 SG_ _96_Resp_Can_ID_val_As m150 : 15|16@0+ (1,0) [0|0] "" Vector__XXX
 SG_ _97_Resp_Can_ID_SN_Wh m151 : 31|32@0+ (1,0) [0|0] "" Vector__XXX
 SG_ _97_Resp_Can_ID_val_Wh m151 : 15|16@0+ (1,0) [0|0] "" Vector__XXX
 SG_ _9D_Resp_Can_ID_SN_Command m157 : 31|32@0+ (1,0) [0|0] "" Vector__XXX
 SG_ _9D_Resp_Can_ID_val_Command m157 : 15|16@0+ (1,0) [0|0] "" Vector__XXX
 SG_ _9F_Resp_Can_ID_SN_Response m159 : 31|32@0+ (1,0) [0|0] "" Vector__XXX
 SG_ _9F_Resp_Can_ID_val_Response m159 : 15|16@0+ (1,0) [0|0] "" Vector__XXX
 SG_ _A0_Resp_CycleTime_I m160 : 23|16@0+ (1,0) [0|0] "ms" Vector__XXX
 SG_ _A0_Resp_Endianess_I m160 : 14|1@0+ (1,0) [0|0] "" Vector__XXX
 SG_ _A0_Resp_Sign_I m160 : 15|1@0+ (1,0) [0|0] "" Vector__XXX
 SG_ _A0_Resp_TriggerMode_I m160 : 9|2@0+ (1,0) [0|2] "" Vector__XXX
 SG_ _A1_Resp_CycleTime_U1 m161 : 23|16@0+ (1,0) [0|0] "ms" Vector__XXX
 SG_ _A1_Resp_Endianess_U1 m161 : 14|1@0+ (1,0) [0|0] "" Vector__XXX
 SG_ _A1_Resp_Sign_U1 m161 : 15|1@0+ (1,0) [0|0] "" Vector__XXX
 SG_ _A1_Resp_TriggerMode_U1 m161 : 9|2@0+ (1,0) [0|2] "" Vector__XXX
 SG_ _A2_Resp_CycleTime_U2 m162 : 23|16@0+ (1,0) [0|0] "ms" Vector__XXX
 SG_ _A2_Resp_Endianess_U2 m162 : 14|1@0+ (1,0) [0|0] "" Vector__XXX
 SG_ _A2_Resp_Sign_U2 m162 : 15|1@0+ (1,0) [0|0] "" Vector__XXX
 SG_ _A2_Resp_TriggerMode_U2 m162 : 9|2@0+ (1,0) [0|2] "" Vector__XXX
 SG_ _A3_Resp_CycleTime_U3 m163 : 23|16@0+ (1,0) [0|0] "ms" Vector__XXX
 SG_ _A3_Resp_Endianess_U3 m163 : 14|1@0+ (1,0) [0|0] "" Vector__XXX
 SG_ _A3_Resp_Sign_U3 m163 : 15|1@0+ (1,0) [0|0] "" Vector__XXX
 SG_ _A3_Resp_TriggerMode_U3 m163 : 9|2@0+ (1,0) [0|2] "" Vector__XXX
 SG_ _A4_Resp_CycleTime_T m164 : 23|16@0+ (1,0) [0|0] "ms" Vector__XXX
 SG_ _A4_Resp_Endianess_T m164 : 14|1@0+ (1,0) [0|0] "" Vector__XXX
 SG_ _A4_Resp_Sign_T m164 : 15|1@0+ (1,0) [0|0] "" Vector__XXX
 SG_ _A4_Resp_TriggerMode_T m164 : 9|2@0+ (1,0) [0|2] "" Vector__XXX
 SG_ _A5_Resp_CycleTime_W m165 : 23|16@0+ (1,0) [0|0] "ms" Vector__XXX
 SG_ _A5_Resp_Endianess_W m165 : 14|1@0+ (1,0) [0|0] "" Vector__XXX
 SG_ _A5_Resp_Sign_W m165 : 15|1@0+ (1,0) [0|0] "" Vector__XXX
 SG_ _A5_Resp_TriggerMode_W m165 : 9|2@0+ (1,0) [0|2] "" Vector__XXX
 SG_ _A6_Resp_CycleTime_As m166 : 23|16@0+ (1,0) [0|0] "ms" Vector__XXX
 SG_ _A6_Resp_Endianess_As m166 : 14|1@0+ (1,0) [0|0] "" Vector__XXX
 SG_ _A6_Resp_Sign_As m166 : 15|1@0+ (1,0) [0|0] "" Vector__XXX
 SG_ _A6_Resp_TriggerMode_As m166 : 9|2@0+ (1,0) [0|2] "" Vector__XXX
 SG_ _A7_Resp_CycleTime_WH m167 : 23|16@0+ (1,0) [0|0] "ms" Vector__XXX
 SG_ _A7_Resp_Endianess_WH m167 : 14|1@0+ (1,0) [0|0] "" Vector__XXX
 SG_ _A7_Resp_Sign_WH m167 : 15|1@0+ (1,0) [0|0] "" Vector__XXX
 SG_ _A7_Resp_TriggerMode_WH m167 : 9|2@0+ (1,0) [0|2] "" Vector__XXX
 SG_ _B0_Resp_Reset_Item m176 : 15|16@0+ (1,0) [0|0] "" Vector__XXX
 SG_ _B0_Resp_Reset_Device_SN m176 : 31|32@0+ (1,0) [0|0] "" Vector__XXX
 SG_ _B2_Resp_Store_dummy m178 : 15|8@0+ (1,0) [0|0] "" Vector__XXX
 SG_ _B3_Resp_Oc_Test_Time m179 : 15|16@0+ (1,0) [0|65535] "ms" Vector__XXX
 SG_ _B4_Resp_Actual_Mode m180 : 8|1@0+ (1,0) [0|0] "" Vector__XXX
 SG_ _B4_Resp_Code_Level m180 : 31|16@0+ (1,0) [0|0] "" Vector__XXX
 SG_ _B4_Resp_Startup_Mode m180 : 16|1@0+ (1,0) [0|0] "" Vector__XXX
 SG_ _B5_Resp_OC_Pos_Reset_Threshold m181 : 31|16@0- (1,0) [0|0] "" Vector__XXX
 SG_ _B5_Resp_OC_Pos_Set_Threshold m181 : 15|16@0- (1,0) [0|0] "" Vector__XXX
 SG_ _B6_Resp_OC_Neg_Reset_Threshold m182 : 31|16@0- (1,0) [0|0] "" Vector__XXX
 SG_ _B6_Resp_OC_Neg_Set_Threshold m182 : 15|16@0- (1,0) [0|0] "" Vector__XXX
 SG_ _B9_Resp_Device_type m185 : 15|8@0+ (1,0) [0|0] "" Vector__XXX
 SG_ _BA_Resp_SW_Ver_Major_HW m186 : 15|8@0+ (1,0) [0|0] "" Vector__XXX
 SG_ _BB_Resp_Serien_Nr m187 : 15|32@0+ (1,0) [0|0] "" Vector__XXX
 SG_ _BC_Resp_Art_N m188 : 15|56@0+ (1,0) [0|0] "" Vector__XXX
 SG_ IVT_ID_Response M : 7|8@0+ (1,0) [0|0] "" Vector__XXX

BO_ 1317 IVT_Msg_Result_T: 6 IVT_Mod
 SG_ IVT_Result_T_System_Error : 15|1@0+ (1,0) [0|0] ""  VCU
 SG_ IVT_Result_T_OCS : 12|1@0+ (1,0) [0|0] ""  VCU
 SG_ IVT_Result_T_Measurement_Error : 14|1@0+ (1,0) [0|0] ""  VCU
 SG_ IVT_Result_T_Channel_Error : 13|1@0+ (1,0) [0|0] ""  VCU
 SG_ IVT_ID_Result_T : 7|8@0+ (1,0) [4|4] ""  VCU
 SG_ IVT_Result_T : 23|32@0- (0.1,0) [-2147483648|2147483647] "°C"  VCU
 SG_ IVT_MsgCount_Result_T : 11|4@0+ (1,0) [0|0] ""  VCU

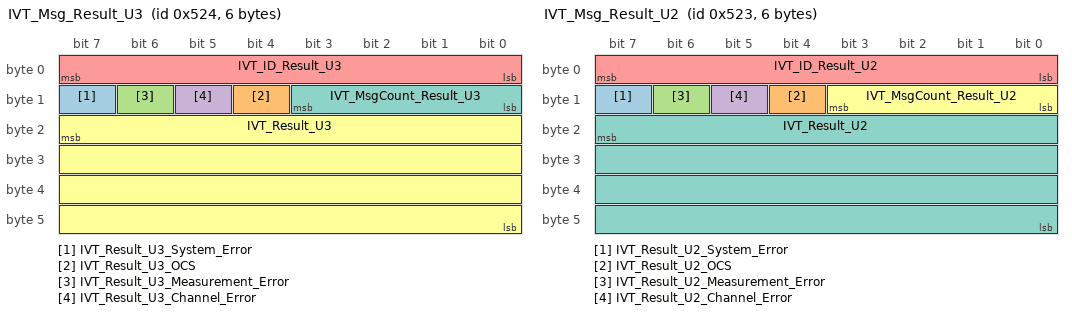
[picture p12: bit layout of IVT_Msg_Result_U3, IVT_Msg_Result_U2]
BO_ 1316 IVT_Msg_Result_U3: 6 IVT_Mod
 SG_ IVT_Result_U3_System_Error : 15|1@0+ (1,0) [0|0] ""  VCU
 SG_ IVT_Result_U3_OCS : 12|1@0+ (1,0) [0|0] ""  VCU
 SG_ IVT_Result_U3_Measurement_Error : 14|1@0+ (1,0) [0|0] ""  VCU
 SG_ IVT_Result_U3_Channel_Error : 13|1@0+ (1,0) [0|0] ""  VCU
 SG_ IVT_ID_Result_U3 : 7|8@0+ (1,0) [3|3] ""  VCU
 SG_ IVT_Result_U3 : 23|32@0- (1,0) [-2147483648|2147483647] "mV"  VCU
 SG_ IVT_MsgCount_Result_U3 : 11|4@0+ (1,0) [0|0] ""  VCU

BO_ 1315 IVT_Msg_Result_U2: 6 IVT_Mod
 SG_ IVT_Result_U2_System_Error : 15|1@0+ (1,0) [0|0] ""  VCU
 SG_ IVT_Result_U2_OCS : 12|1@0+ (1,0) [0|0] ""  VCU
 SG_ IVT_Result_U2_Measurement_Error : 14|1@0+ (1,0) [0|0] ""  VCU
 SG_ IVT_Result_U2_Channel_Error : 13|1@0+ (1,0) [0|0] ""  VCU
 SG_ IVT_ID_Result_U2 : 7|8@0+ (1,0) [2|2] ""  VCU
 SG_ IVT_MsgCount_Result_U2 : 11|4@0+ (1,0) [0|0] ""  VCU
 SG_ IVT_Result_U2 : 23|32@0- (1,0) [-2147483648|2147483647] "mV"  VCU

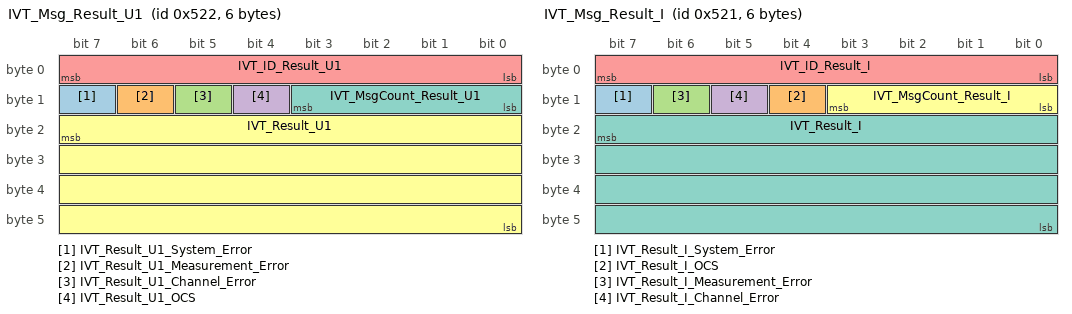
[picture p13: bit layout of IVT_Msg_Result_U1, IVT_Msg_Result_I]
BO_ 1314 IVT_Msg_Result_U1: 6 IVT_Mod
 SG_ IVT_Result_U1_System_Error : 15|1@0+ (1,0) [0|0] ""  VCU
 SG_ IVT_Result_U1_Measurement_Error : 14|1@0+ (1,0) [0|0] ""  VCU
 SG_ IVT_Result_U1_Channel_Error : 13|1@0+ (1,0) [0|0] ""  VCU
 SG_ IVT_Result_U1_OCS : 12|1@0+ (1,0) [0|0] ""  VCU
 SG_ IVT_ID_Result_U1 : 7|8@0+ (1,0) [1|1] ""  VCU
 SG_ IVT_Result_U1 : 23|32@0- (1,0) [-2147483648|2147483647] "mV"  VCU
 SG_ IVT_MsgCount_Result_U1 : 11|4@0+ (1,0) [0|0] ""  VCU

BO_ 1313 IVT_Msg_Result_I: 6 IVT_Mod
 SG_ IVT_Result_I_System_Error : 15|1@0+ (1,0) [0|0] ""  VCU
 SG_ IVT_Result_I_OCS : 12|1@0+ (1,0) [0|0] ""  VCU
 SG_ IVT_Result_I_Measurement_Error : 14|1@0+ (1,0) [0|0] ""  VCU
 SG_ IVT_Result_I_Channel_Error : 13|1@0+ (1,0) [0|0] ""  VCU
 SG_ IVT_ID_Result_I : 7|8@0+ (1,0) [0|0] ""  VCU
 SG_ IVT_MsgCount_Result_I : 11|4@0+ (1,0) [0|0] ""  VCU
 SG_ IVT_Result_I : 23|32@0- (1,0) [-2147483648|2147483647] "mA"  VCU

BO_ 1041 IVT_Msg_Cmd: 8 VCU
 SG_ _31_01_Trigger_U1 m49 : 17|1@0+ (1,0) [0|0] "" Vector__XXX
 SG_ _31_07_Trigger_WH m49 : 23|1@0+ (1,0) [0|0] "" Vector__XXX
 SG_ _31_06_Trigger_As m49 : 22|1@0+ (1,0) [0|0] "" Vector__XXX
 SG_ _31_05_Trigger_W m49 : 21|1@0+ (1,0) [0|0] "" Vector__XXX
 SG_ _31_04_Trigger_T m49 : 20|1@0+ (1,0) [0|0] "" Vector__XXX
 SG_ _31_03_Trigger_U3 m49 : 19|1@0+ (1,0) [0|0] "" Vector__XXX
 SG_ _31_Trigger_spare m49 : 15|8@0+ (1,0) [0|0] "" Vector__XXX
 SG_ _31_02_Trigger_U2 m49 : 18|1@0+ (1,0) [0|0] "" Vector__XXX
 SG_ _10_Set_Can_ID_SN_I m16 : 31|32@0+ (1,0) [0|0] "" Vector__XXX
 SG_ _10_Set_Can_ID_val_I m16 : 15|16@0+ (1,0) [0|2047] ""  IVT_Mod
 SG_ _11_Set_Can_ID_SN_U1 m17 : 31|32@0+ (1,0) [0|0] "" Vector__XXX
 SG_ _11_Set_Can_ID_val_U1 m17 : 15|16@0+ (1,0) [0|2047] "" Vector__XXX
 SG_ _12_Set_Can_ID_SN_U2 m18 : 31|32@0+ (1,0) [0|0] "" Vector__XXX
 SG_ _12_Set_Can_ID_val_U2 m18 : 15|16@0+ (1,0) [0|2047] "" Vector__XXX
 SG_ _13_Set_Can_ID_SN_U3 m19 : 31|32@0+ (1,0) [0|0] "" Vector__XXX
 SG_ _13_Set_Can_ID_val_U3 m19 : 15|16@0+ (1,0) [0|2047] "" Vector__XXX
 SG_ _14_Set_Can_ID_SN_T m20 : 31|32@0+ (1,0) [0|0] "" Vector__XXX
 SG_ _14_Set_Can_ID_val_T m20 : 15|16@0+ (1,0) [0|2047] "" Vector__XXX
 SG_ _15_Set_Can_ID_SN_W m21 : 31|32@0+ (1,0) [0|0] "" Vector__XXX
 SG_ _15_Set_Can_ID_val_W m21 : 15|16@0+ (1,0) [0|2047] "" Vector__XXX
 SG_ _16_Set_Can_ID_SN_As m22 : 31|32@0+ (1,0) [0|0] "" Vector__XXX
 SG_ _16_Set_Can_ID_val_As m22 : 15|16@0+ (1,0) [0|2047] "" Vector__XXX
 SG_ _17_Set_Can_ID_SN_Wh m23 : 31|32@0+ (1,0) [0|0] "" Vector__XXX
 SG_ _17_Set_Can_ID_val_Wh m23 : 15|16@0+ (1,0) [0|2047] "" Vector__XXX
 SG_ _1D_Set_Can_ID_SN_Command m29 : 31|32@0+ (1,0) [0|0] "" Vector__XXX
 SG_ _1D_Set_Can_ID_val_Command m29 : 15|16@0+ (1,0) [0|2047] "" Vector__XXX
 SG_ _1F_Set_Can_ID_SN_Response m31 : 31|32@0+ (1,0) [0|0] "" Vector__XXX
 SG_ _1F_Set_Can_ID_val_Response m31 : 15|16@0+ (1,0) [0|2047] "" Vector__XXX
 SG_ _20_Conf_CycleTime_I m32 : 23|16@0+ (1,0) [0|0] "ms" Vector__XXX
 SG_ _20_Conf_Endianess_I m32 : 14|1@0+ (1,0) [0|0] "" Vector__XXX
 SG_ _20_Conf_Sign_I m32 : 15|1@0+ (1,0) [0|0] "" Vector__XXX
 SG_ _20_Conf_TriggerMode_I m32 : 9|2@0+ (1,0) [0|2] "" Vector__XXX
 SG_ _21_Conf_CycleTime_U1 m33 : 23|16@0+ (1,0) [0|0] "ms" Vector__XXX
 SG_ _21_Conf_Endianess_U1 m33 : 14|1@0+ (1,0) [0|0] "" Vector__XXX
 SG_ _21_Conf_Sign_U1 m33 : 15|1@0+ (1,0) [0|0] "" Vector__XXX
 SG_ _21_Conf_TriggerMode_U1 m33 : 9|2@0+ (1,0) [0|2] "" Vector__XXX
 SG_ _22_Conf_CycleTime_U2 m34 : 23|16@0+ (1,0) [0|0] "ms" Vector__XXX
 SG_ _22_Conf_Endianess_U2 m34 : 14|1@0+ (1,0) [0|0] "" Vector__XXX
 SG_ _22_Conf_Sign_U2 m34 : 15|1@0+ (1,0) [0|0] "" Vector__XXX
 SG_ _22_Conf_TriggerMode_U2 m34 : 9|2@0+ (1,0) [0|2] "" Vector__XXX
 SG_ _23_Conf_CycleTime_U3 m35 : 23|16@0+ (1,0) [0|0] "ms" Vector__XXX
 SG_ _23_Conf_Endianess_U3 m35 : 14|1@0+ (1,0) [0|0] "" Vector__XXX
 SG_ _23_Conf_Sign_U3 m35 : 15|1@0+ (1,0) [0|0] "" Vector__XXX
 SG_ _23_Conf_TriggerMode_U3 m35 : 9|2@0+ (1,0) [0|2] "" Vector__XXX
 SG_ _24_Conf_CycleTime_T m36 : 23|16@0+ (1,0) [0|0] "ms" Vector__XXX
 SG_ _24_Conf_Endianess_T m36 : 14|1@0+ (1,0) [0|0] "" Vector__XXX
 SG_ _24_Conf_Sign_T m36 : 15|1@0+ (1,0) [0|0] "" Vector__XXX
 SG_ _24_Conf_TriggerMode_T m36 : 9|2@0+ (1,0) [0|2] "" Vector__XXX
 SG_ _25_Conf_CycleTime_W m37 : 23|16@0+ (1,0) [0|0] "ms" Vector__XXX
 SG_ _25_Conf_Endianess_W m37 : 14|1@0+ (1,0) [0|0] "" Vector__XXX
 SG_ _25_Conf_Sign_W m37 : 15|1@0+ (1,0) [0|0] "" Vector__XXX
 SG_ _25_Conf_TriggerMode_W m37 : 9|2@0+ (1,0) [0|2] "" Vector__XXX
 SG_ _26_Conf_CycleTime_As m38 : 23|16@0+ (1,0) [0|0] "ms" Vector__XXX
 SG_ _26_Conf_Endianess_As m38 : 14|1@0+ (1,0) [0|0] "" Vector__XXX
 SG_ _26_Conf_Sign_As m38 : 15|1@0+ (1,0) [0|0] "" Vector__XXX
 SG_ _26_Conf_TriggerMode_As m38 : 9|2@0+ (1,0) [0|2] "" Vector__XXX
 SG_ _27_Conf_CycleTime_WH m39 : 23|16@0+ (1,0) [0|0] "ms" Vector__XXX
 SG_ _27_Conf_Endianess_WH m39 : 14|1@0+ (1,0) [0|0] "" Vector__XXX
 SG_ _27_Conf_Sign_WH m39 : 15|1@0+ (1,0) [0|0] "" Vector__XXX
 SG_ _27_Conf_TriggerMode_WH m39 : 9|2@0+ (1,0) [0|2] "" Vector__XXX
 SG_ _30_Reset_Item m48 : 15|16@0+ (1,0) [0|0] "" Vector__XXX
 SG_ _30_Reset_Device_SN m48 : 31|32@0+ (1,0) [0|0] "" Vector__XXX
 SG_ _31_00_Trigger_I m49 : 16|1@0+ (1,0) [0|0] "" Vector__XXX
 SG_ _32_Store_dummy m50 : 15|8@0+ (1,0) [0|0] "" Vector__XXX
 SG_ _33_Oc_Test_Time m51 : 15|16@0+ (1,0) [0|65535] "ms" Vector__XXX
 SG_ _34_Actual_Mode m52 : 8|1@0+ (1,0) [0|0] "" Vector__XXX
 SG_ _34_Code_Level m52 : 31|16@0+ (1,0) [0|0] "" Vector__XXX
 SG_ _34_Startup_Mode m52 : 16|1@0+ (1,0) [0|0] "" Vector__XXX
 SG_ _35_OC_Pos_Reset_Threshold m53 : 31|16@0- (1,0) [0|0] "A" Vector__XXX
 SG_ _35_OC_Pos_Set_Threshold m53 : 15|16@0- (1,0) [0|0] "A" Vector__XXX
 SG_ _36_OC_Neg_Reset_Threshold m54 : 31|16@0- (1,0) [0|0] "A" Vector__XXX
 SG_ _36_OC_Neg_Set_Threshold m54 : 15|16@0- (1,0) [0|0] "A" Vector__XXX
 SG_ _3A_RESTART_to_Bitrate m58 : 15|8@0+ (1,0) [0|0] "" Vector__XXX
 SG_ _3D_Restart_Default_Dummy m61 : 15|8@0+ (1,0) [0|0] "" Vector__XXX
 SG_ _3F_Restart_Dummy m63 : 15|8@0+ (1,0) [0|0] "" Vector__XXX
 SG_ _40_Get_MeasError_Item m64 : 15|8@0+ (1,0) [0|0] "" Vector__XXX
 SG_ _41_Get_SystemError_Item m65 : 15|8@0+ (1,0) [0|0] "" Vector__XXX
 SG_ _42_Get_AllLogData_Item m66 : 15|8@0+ (1,0) [0|0] "" Vector__XXX
 SG_ _43_Get_LogData_Item m67 : 15|8@0+ (1,0) [0|0] "" Vector__XXX
 SG_ _50_Get_Can_ID_SN_I m80 : 31|32@0+ (1,0) [0|0] "" Vector__XXX
 SG_ _51_Get_Can_ID_SN_U1 m81 : 31|32@0+ (1,0) [0|0] "" Vector__XXX
 SG_ _52_Get_Can_ID_SN_U2 m82 : 31|32@0+ (1,0) [0|0] "" Vector__XXX
 SG_ _53_Get_Can_ID_SN_U3 m83 : 31|32@0+ (1,0) [0|0] "" Vector__XXX
 SG_ _54_Get_Can_ID_SN_T m84 : 31|32@0+ (1,0) [0|0] "" Vector__XXX
 SG_ _55_Get_Can_ID_SN_W m85 : 31|32@0+ (1,0) [0|0] "" Vector__XXX
 SG_ _56_Get_Can_ID_SN_As m86 : 31|32@0+ (1,0) [0|0] "" Vector__XXX
 SG_ _57_Get_Can_ID_SN_Wh m87 : 31|32@0+ (1,0) [0|0] "" Vector__XXX
 SG_ _5D_Get_Can_ID_SN_Command m93 : 31|32@0+ (1,0) [0|0] "" Vector__XXX
 SG_ _5F_Get_Can_ID_SN_Response m95 : 31|32@0+ (1,0) [0|0] "" Vector__XXX
 SG_ _60_Get_Result_dummy_I m96 : 15|8@0+ (1,0) [0|0] "" Vector__XXX
 SG_ _61_Get_Result_dummy_U1 m97 : 15|8@0+ (1,0) [0|0] "" Vector__XXX
 SG_ _62_Get_Result_dummy_U2 m98 : 15|8@0+ (1,0) [0|0] "" Vector__XXX
 SG_ _63_Get_Result_dummy_U3 m99 : 15|8@0+ (1,0) [0|0] "" Vector__XXX
 SG_ _64_Get_Result_dummy_T m100 : 15|8@0+ (1,0) [0|0] "" Vector__XXX
 SG_ _65_Get_Result_dummy_W m101 : 15|8@0+ (1,0) [0|0] "" Vector__XXX
 SG_ _66_Get_Result_dummy_As m102 : 15|8@0+ (1,0) [0|0] "" Vector__XXX
 SG_ _67_Get_Result_dummy_Wh m103 : 15|8@0+ (1,0) [0|0] "" Vector__XXX
 SG_ _73_Get_OC_Test_dummy m115 : 15|8@0+ (1,0) [0|0] "" Vector__XXX
 SG_ _74_Get_Mode_dummy m116 : 15|8@0+ (1,0) [0|0] "" Vector__XXX
 SG_ _75_Get_OC_Pos_dummy m117 : 15|8@0+ (1,0) [0|0] "" Vector__XXX
 SG_ _76_Get_OC_Neg_dummy m118 : 15|8@0+ (1,0) [0|0] "" Vector__XXX
 SG_ _79_Get_Device_Id_dummy m121 : 15|8@0+ (1,0) [0|0] "" Vector__XXX
 SG_ _7A_Get_SW_Version_dummy m122 : 15|8@0+ (1,0) [0|0] "" Vector__XXX
 SG_ _7B_Get_Serien_Nr_dummy m123 : 15|8@0+ (1,0) [0|0] "" Vector__XXX
 SG_ _7C_Get_Art_Nr_dummy m124 : 15|8@0+ (1,0) [0|0] "" Vector__XXX
 SG_ IVT_ID_Cmd M : 7|8@0+ (1,0) [0|0] ""  IVT_Mod

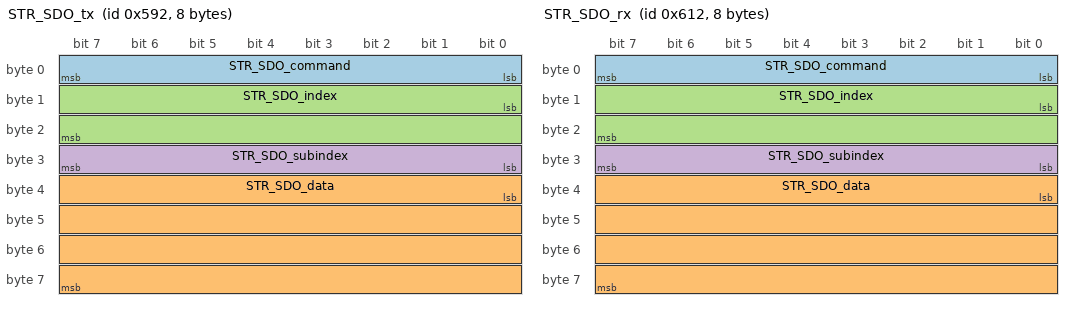
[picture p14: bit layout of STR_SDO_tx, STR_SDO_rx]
BO_ 1426 STR_SDO_tx: 8 Third_Party
 SG_ STR_SDO_command : 0|8@1+ (1,0) [0|0] ""  VCU
 SG_ STR_SDO_data : 32|32@1- (1,0) [-2147483648|2147483647] ""  VCU
 SG_ STR_SDO_index : 8|16@1+ (1,0) [0|32767] ""  VCU
 SG_ STR_SDO_subindex : 24|8@1+ (1,0) [0|255] ""  VCU

BO_ 1554 STR_SDO_rx: 8 VCU
 SG_ STR_SDO_command : 0|8@1+ (1,0) [0|0] ""  Third_Party
 SG_ STR_SDO_data : 32|32@1- (1,0) [-2147483648|2147483647] ""  Third_Party
 SG_ STR_SDO_index : 8|16@1+ (1,0) [0|32767] ""  Third_Party
 SG_ STR_SDO_subindex : 24|8@1+ (1,0) [0|255] ""  Third_Party

BO_ 1664 CAN_Flash_RX: 8 Third_Party

BO_ 1665 CAN_Flash_SMU_RL_TX: 8 Third_Party

BO_ 1666 CAN_Flash_SMU_RR_TX: 8 Third_Party

BO_ 1667 CAN_Flash_SMU_F_TX: 8 Third_Party

BO_ 1668 CAN_Flash_SMU_PB_TX: 8 Third_Party

BO_ 1670 CAN_Flash_ASI_TX: 8 VCU

BO_ 1672 CAN_Flash_DMI_TX: 8 Third_Party

BO_ 1673 CAN_Flash_SMU_AD_TX: 8 Third_Party

BO_ 1675 CAN_Flash_SMU_TESTBENCH_TX: 8 Third_Party

BO_ 1676 CAN_Flash_DCDC_ACTIVATION: 8 Third_Party

BO_ 1679 CAN_Flash_SMU_test: 8 VCU

BO_ 1760 CANopen_reserved_dynamic_sdo: 8 Third_Party

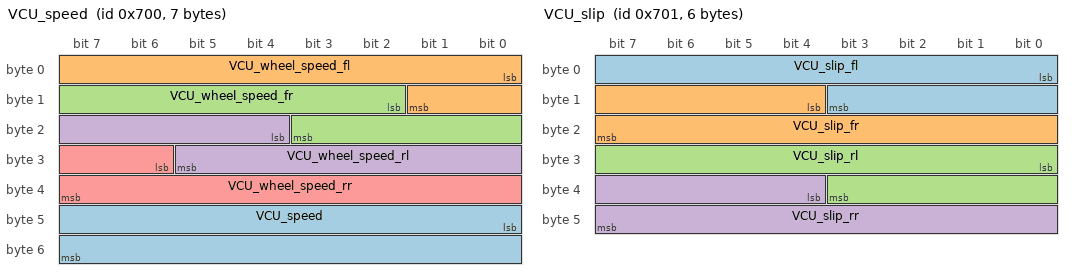
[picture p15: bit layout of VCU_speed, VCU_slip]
BO_ 1792 VCU_speed: 7 VCU
 SG_ VCU_speed : 40|16@1- (0.005,0) [-163.84|163.835] "m/s"  Third_Party
 SG_ VCU_wheel_speed_fl : 0|10@1- (0.2,50) [-52.4|152.2] "m/s"  Third_Party
 SG_ VCU_wheel_speed_fr : 10|10@1- (0.2,50) [-52.4|152.2] "m/s"  Third_Party
 SG_ VCU_wheel_speed_rl : 20|10@1- (0.2,50) [-52.4|152.2] "m/s"  Third_Party
 SG_ VCU_wheel_speed_rr : 30|10@1- (0.2,50) [-52.4|152.2] "m/s"  Third_Party

BO_ 1793 VCU_slip: 6 VCU
 SG_ VCU_slip_fl : 0|12@1- (0.001,0) [-2.048|2.047] "%"  Third_Party
 SG_ VCU_slip_fr : 12|12@1- (0.001,0) [-2.048|2.047] "%"  Third_Party
 SG_ VCU_slip_rl : 24|12@1- (0.001,0) [-2.048|2.047] "%"  Third_Party
 SG_ VCU_slip_rr : 36|12@1- (0.001,0) [-2.048|2.047] "%"  Third_Party

BO_ 1794 VCU_inverter_state: 7 VCU
 SG_ VCU_INV_fault : 40|1@1+ (1,0) [0|1] ""  Third_Party
 SG_ VCU_INV_fault_reaction_active : 41|1@1+ (1,0) [0|1] ""  Third_Party
 SG_ VCU_INV_field_weakening_active : 42|1@1+ (1,0) [0|1] ""  Third_Party
 SG_ VCU_INV_not_ready_to_switch_on : 43|1@1+ (1,0) [0|1] ""  Third_Party
 SG_ VCU_INV_operation_enabled : 44|1@1+ (1,0) [0|1] ""  Third_Party
 SG_ VCU_INV_quick_stop_active : 45|1@1+ (1,0) [0|1] ""  Third_Party
 SG_ VCU_INV_ready_to_switch_on : 46|1@1+ (1,0) [0|1] ""  Third_Party
 SG_ VCU_INV_switch_on_disabled : 47|1@1+ (1,0) [0|1] ""  Third_Party
 SG_ VCU_INV_switched_on : 48|1@1+ (1,0) [0|1] ""  Third_Party
 SG_ VCU_INV_voltage_enabled : 49|1@1+ (1,0) [0|1] ""  Third_Party
 SG_ VCU_inv_fl_active : 0|1@1+ (1,0) [0|1] ""  Third_Party
 SG_ VCU_inv_fl_error : 1|1@1+ (1,0) [0|1] ""  Third_Party
 SG_ VCU_inv_fl_state : 8|8@1+ (1,0) [0|255] ""  Third_Party
 SG_ VCU_inv_fr_active : 2|1@1+ (1,0) [0|1] ""  Third_Party
 SG_ VCU_inv_fr_error : 3|1@1+ (1,0) [0|1] ""  Third_Party
 SG_ VCU_inv_fr_state : 16|8@1+ (1,0) [0|255] ""  Third_Party
 SG_ VCU_inv_rl_active : 4|1@1+ (1,0) [0|1] ""  Third_Party
 SG_ VCU_inv_rl_error : 5|1@1+ (1,0) [0|1] ""  Third_Party
 SG_ VCU_inv_rl_state : 24|8@1+ (1,0) [0|255] ""  Third_Party
 SG_ VCU_inv_rr_active : 6|1@1+ (1,0) [0|1] ""  Third_Party
 SG_ VCU_inv_rr_error : 7|1@1+ (1,0) [0|1] ""  Third_Party
 SG_ VCU_inv_rr_state : 32|8@1+ (1,0) [0|255] ""  Third_Party

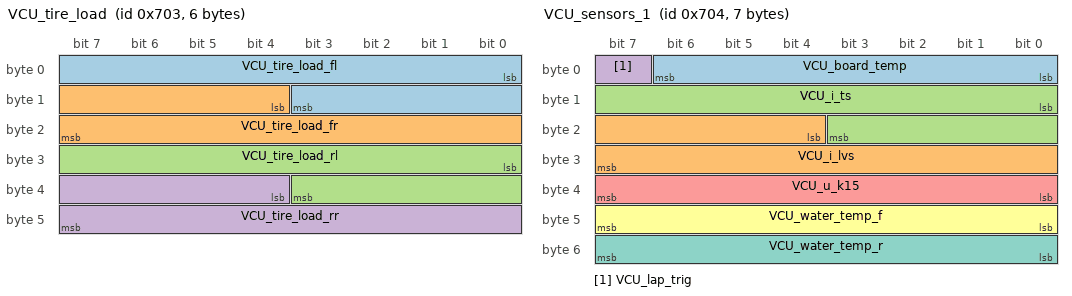
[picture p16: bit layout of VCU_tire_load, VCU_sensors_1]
BO_ 1795 VCU_tire_load: 6 VCU
 SG_ VCU_tire_load_fl : 0|12@1- (1,1000) [-1048|3047] "N"  Third_Party
 SG_ VCU_tire_load_fr : 12|12@1- (1,1000) [-1048|3047] "N"  Third_Party
 SG_ VCU_tire_load_rl : 24|12@1- (1,1000) [-1048|3047] "N"  Third_Party
 SG_ VCU_tire_load_rr : 36|12@1- (1,1000) [-1048|3047] "N"  Third_Party

BO_ 1796 VCU_sensors_1: 7 VCU
 SG_ VCU_board_temp : 0|7@1- (1,50) [-14|113] "ï¿½C"  Third_Party
 SG_ VCU_i_lvs : 20|12@1- (0.037,0) [-75.776|75.739] "A"  Third_Party
 SG_ VCU_i_ts : 8|12@1- (0.042,0) [-86.016|85.974] "A"  Third_Party
 SG_ VCU_lap_trig : 7|1@1+ (1,0) [0|1] ""  Third_Party
 SG_ VCU_u_k15 : 32|8@1+ (0.12,0) [0|30.6] "V"  Third_Party
 SG_ VCU_water_temp_f : 40|8@1+ (0.4,0) [0|102] "ï¿½C"  Third_Party
 SG_ VCU_water_temp_r : 48|8@1+ (0.4,0) [0|102] "ï¿½C"  Third_Party

BO_ 1797 VCU_sensors_2: 2 VCU
 SG_ VCU_flow_f : 0|8@1+ (0.1,0) [0|25.5] "l/min"  Third_Party
 SG_ VCU_flow_r : 8|8@1+ (0.1,0) [0|25.5] "l/min"  Third_Party

BO_ 1798 VCU_odometer: 8 VCU
 SG_ VCU_odometer : 0|16@1+ (5,0) [0|327675] "m"  Third_Party

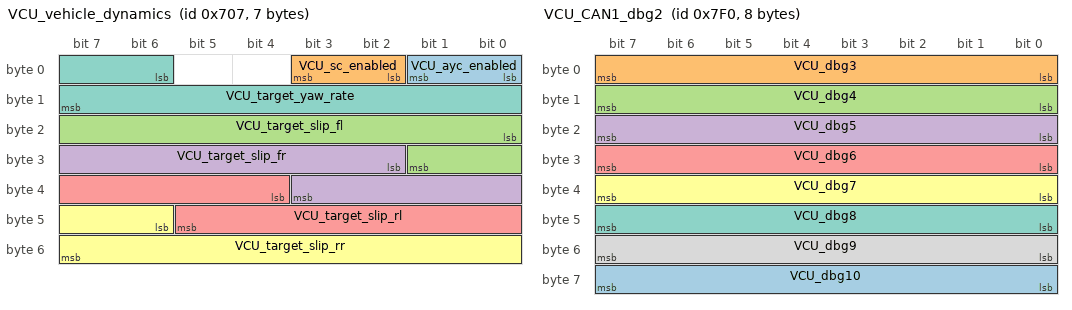
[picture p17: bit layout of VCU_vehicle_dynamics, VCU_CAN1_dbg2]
BO_ 1799 VCU_vehicle_dynamics: 7 VCU
 SG_ VCU_ayc_enabled : 0|2@1+ (1,0) [0|3] ""  Third_Party
 SG_ VCU_sc_enabled : 2|2@1+ (1,0) [0|3] ""  Third_Party
 SG_ VCU_target_slip_fl : 16|10@1- (0.004,0) [-2.048|2.044] ""  Third_Party
 SG_ VCU_target_slip_fr : 26|10@1- (0.004,0) [-2.048|2.044] ""  Third_Party
 SG_ VCU_target_slip_rl : 36|10@1- (0.004,0) [-2.048|2.044] ""  Third_Party
 SG_ VCU_target_slip_rr : 46|10@1- (0.004,0) [-2.048|2.044] ""  Third_Party
 SG_ VCU_target_yaw_rate : 6|10@1- (0.01,0) [-5.12|5.11] "rad/s"  Third_Party

BO_ 1800 VCU_lap_time: 3 VCU
 SG_ VCU_lap_complete : 16|1@1+ (1,0) [0|1] ""  Third_Party
 SG_ VCU_lap_time : 0|16@1+ (0.01,0) [0|655.35] "s"  Third_Party

BO_ 1809 VCU_dbc_git_hash: 8 VCU
 SG_ VCU_dbc_git_hash : 0|64@1- (1,0) [-9.22337203685478E+18|9.22337203685478E+18] ""  Third_Party

BO_ 1810 STR_reserved_NMT: 8 Third_Party

BO_ 2020 CANopen_reserved_LSS_tx: 8 Third_Party

BO_ 2021 CANopen_reserved_LSS_rx: 8 Third_Party

BO_ 2032 VCU_CAN1_dbg2: 8 VCU
 SG_ VCU_dbg10 : 56|8@1+ (1,0) [0|255] ""  Third_Party
 SG_ VCU_dbg3 : 0|8@1- (1,0) [-128|127] ""  Third_Party
 SG_ VCU_dbg4 : 8|8@1+ (1,0) [0|255] ""  Third_Party
 SG_ VCU_dbg5 : 16|8@1- (1,0) [-128|127] ""  Third_Party
 SG_ VCU_dbg6 : 24|8@1+ (1,0) [0|255] ""  Third_Party
 SG_ VCU_dbg7 : 32|8@1+ (1,0) [0|255] ""  Third_Party
 SG_ VCU_dbg8 : 40|8@1+ (1,0) [0|255] ""  Third_Party
 SG_ VCU_dbg9 : 48|8@1+ (1,0) [0|255] ""  Third_Party

BO_ 2047 VCU_CAN1_dbg: 8 VCU
 SG_ VCU_dbg1 : 0|32@1- (1,0) [-3.39999995214436E+38|3.39999995214436E+38] ""  Third_Party
 SG_ VCU_dbg2 : 32|32@1- (1,0) [-3.39999995214436E+38|3.39999995214436E+38] ""  Third_Party

CM_ BO_ 3221225472 "This is a message for not used signals, created by Vector CANdb++ DBC OLE DB Provider.";
CM_ SG_ 352 VCU_diag_state_error "Should have a value table, but the table is very long and i dont really have the time to do it now. well se how important this signal really is...";
CM_ SG_ 352 VCU_exec_time "Execution time of the VCU Software in ms. should never be above 5ms, so a range from 0-6ms is probably enough";
BA_DEF_  "DBName" STRING ;
BA_DEF_ BO_  "GenMsgCycleTime" INT 0 0;
BA_DEF_ BO_  "GenMsgSendType" ENUM  "Cyclic","OnEvent";
BA_DEF_ SG_  "GenSigSendType" ENUM  "NoSigSendType";
BA_DEF_ SG_  "GenSigStartValue" INT 0 0;
BA_DEF_ SG_  "SPN" INT 0 524287;
BA_DEF_DEF_  "DBName" "";
BA_DEF_DEF_  "GenMsgCycleTime" 0;
BA_DEF_DEF_  "GenMsgSendType" "";
BA_DEF_DEF_  "GenSigSendType" "";
BA_DEF_DEF_  "GenSigStartValue" 0;
BA_DEF_DEF_  "SPN" 0;
BA_ "DBName" "CAN1";
BA_ "GenMsgSendType" BO_ 52 1;
BA_ "GenMsgSendType" BO_ 0 1;
BA_ "GenMsgSendType" BO_ 1 1;
BA_ "GenMsgSendType" BO_ 48 1;
BA_ "GenMsgSendType" BO_ 50 1;
BA_ "GenMsgSendType" BO_ 518 1;
BA_ "GenMsgSendType" BO_ 69 1;
BA_ "GenMsgSendType" BO_ 70 1;
BA_ "GenMsgSendType" BO_ 71 1;
BA_ "GenMsgSendType" BO_ 72 1;
BA_ "GenMsgSendType" BO_ 512 1;
BA_ "GenMsgSendType" BO_ 88 0;
BA_ "GenMsgCycleTime" BO_ 88 100;
BA_ "GenMsgSendType" BO_ 514 1;
BA_ "GenMsgSendType" BO_ 127 1;
BA_ "GenMsgSendType" BO_ 128 1;
BA_ "GenMsgSendType" BO_ 146 1;
BA_ "GenMsgSendType" BO_ 322 1;
BA_ "GenMsgSendType" BO_ 336 1;
BA_ "GenMsgSendType" BO_ 338 1;
BA_ "GenMsgSendType" BO_ 340 1;
BA_ "GenMsgSendType" BO_ 344 1;
BA_ "GenMsgSendType" BO_ 346 1;
BA_ "GenMsgSendType" BO_ 348 1;
BA_ "GenMsgSendType" BO_ 349 1;
BA_ "GenMsgSendType" BO_ 352 1;
BA_ "GenMsgSendType" BO_ 515 1;
BA_ "GenMsgSendType" BO_ 516 1;
BA_ "GenMsgSendType" BO_ 517 1;
BA_ "GenMsgSendType" BO_ 530 1;
BA_ "GenMsgSendType" BO_ 534 1;
BA_ "GenMsgSendType" BO_ 600 1;
BA_ "GenMsgSendType" BO_ 601 1;
BA_ "GenMsgSendType" BO_ 602 1;
BA_ "GenMsgSendType" BO_ 768 0;
BA_ "GenMsgCycleTime" BO_ 768 100;
BA_ "GenMsgSendType" BO_ 769 1;
BA_ "GenMsgSendType" BO_ 786 1;
BA_ "GenMsgSendType" BO_ 788 1;
BA_ "GenMsgSendType" BO_ 789 1;
BA_ "GenMsgSendType" BO_ 790 1;
BA_ "GenMsgSendType" BO_ 791 1;
BA_ "GenMsgSendType" BO_ 792 1;
BA_ "GenMsgSendType" BO_ 794 1;
BA_ "GenMsgSendType" BO_ 796 1;
BA_ "GenMsgSendType" BO_ 798 1;
BA_ "GenMsgSendType" BO_ 1299 1;
BA_ "GenMsgSendType" BO_ 1300 1;
BA_ "GenMsgSendType" BO_ 1426 0;
BA_ "GenMsgSendType" BO_ 1554 0;
BA_ "GenMsgSendType" BO_ 1664 1;
BA_ "GenMsgSendType" BO_ 1665 1;
BA_ "GenMsgSendType" BO_ 1666 1;
BA_ "GenMsgSendType" BO_ 1667 1;
BA_ "GenMsgSendType" BO_ 1668 1;
BA_ "GenMsgSendType" BO_ 1670 0;
BA_ "GenMsgCycleTime" BO_ 1670 100;
BA_ "GenMsgSendType" BO_ 1672 1;
BA_ "GenMsgSendType" BO_ 1673 1;
BA_ "GenMsgSendType" BO_ 1675 1;
BA_ "GenMsgSendType" BO_ 1676 1;
BA_ "GenMsgSendType" BO_ 1679 0;
BA_ "GenMsgCycleTime" BO_ 1679 100;
BA_ "GenMsgSendType" BO_ 1760 1;
BA_ "GenMsgSendType" BO_ 1792 1;
BA_ "GenMsgSendType" BO_ 1793 1;
BA_ "GenMsgSendType" BO_ 1794 1;
BA_ "GenMsgSendType" BO_ 1795 1;
BA_ "GenMsgSendType" BO_ 1796 1;
BA_ "GenMsgSendType" BO_ 1797 1;
BA_ "GenMsgSendType" BO_ 1798 1;
BA_ "GenMsgSendType" BO_ 1799 1;
BA_ "GenMsgSendType" BO_ 1800 1;
BA_ "GenMsgSendType" BO_ 1809 1;
BA_ "GenMsgSendType" BO_ 1810 1;
BA_ "GenMsgSendType" BO_ 2020 1;
BA_ "GenMsgSendType" BO_ 2021 1;
BA_ "GenMsgSendType" BO_ 2032 1;
BA_ "GenMsgSendType" BO_ 2047 1;
BA_ "GenSigSendType" SG_ 1320 IVT_Result_Wh 7;
BA_ "GenSigSendType" SG_ 1320 IVT_ID_Result_Wh 7;
BA_ "GenSigStartValue" SG_ 1320 IVT_ID_Result_Wh 7;
BA_ "GenSigSendType" SG_ 1319 IVT_ID_Result_As 7;
BA_ "GenSigStartValue" SG_ 1319 IVT_ID_Result_As 6;
BA_ "GenSigSendType" SG_ 1318 IVT_ID_Result_W 7;
BA_ "GenSigStartValue" SG_ 1318 IVT_ID_Result_W 5;
BA_ "GenSigStartValue" SG_ 1297 _A0_Resp_TriggerMode_I 2;
BA_ "GenSigStartValue" SG_ 1297 _A4_Resp_TriggerMode_T 2;
BA_ "GenSigStartValue" SG_ 1297 _A5_Resp_TriggerMode_W 2;
BA_ "GenSigStartValue" SG_ 1297 _A6_Resp_TriggerMode_As 2;
BA_ "GenSigStartValue" SG_ 1297 _A7_Resp_TriggerMode_WH 2;
BA_ "GenSigSendType" SG_ 1317 IVT_ID_Result_T 7;
BA_ "GenSigStartValue" SG_ 1317 IVT_ID_Result_T 4;
BA_ "GenSigSendType" SG_ 1316 IVT_ID_Result_U3 7;
BA_ "GenSigStartValue" SG_ 1316 IVT_ID_Result_U3 3;
BA_ "GenSigSendType" SG_ 1315 IVT_ID_Result_U2 7;
BA_ "GenSigStartValue" SG_ 1315 IVT_ID_Result_U2 2;
BA_ "GenSigSendType" SG_ 1314 IVT_ID_Result_U1 7;
BA_ "GenSigStartValue" SG_ 1314 IVT_ID_Result_U1 1;
BA_ "GenSigSendType" SG_ 1314 IVT_Result_U1 7;
BA_ "GenSigSendType" SG_ 1313 IVT_ID_Result_I 7;
BA_ "GenSigSendType" SG_ 1313 IVT_Result_I 7;
VAL_ 1320 IVT_ID_Result_Wh 7 "Vt_Result_Wh" ;
VAL_ 1319 IVT_ID_Result_As 6 "Vt_Result_As" ;
VAL_ 1318 IVT_ID_Result_W 5 "Vt_Result_W" ;
VAL_ 1297 _B9_Resp_Device_Com 2 "CAN 2 - not terminated" 1 "CAN 1 - terminated" 0 "none" ;
VAL_ 1297 _B9_Resp_Device_current 2500 "2500 A" 1000 "1000 A" 500 "500 A" 300 "300 A" 100 "100 A" ;
VAL_ 1297 _B9_Resp_Device_TOI 3 "I" ;
VAL_ 1297 _B9_Resp_Device_V_supply 1 "12 / 24 V nominal supply voltage" ;
VAL_ 1297 _B9_Resp_Device_Voltage_chan 3 "3 Channels" 0 "0 Channels" ;
VAL_ 1297 _80_Resp_MeasError_Item 15 "Resp error calibration data" 14 "Resp error ntc-I OpenCirc" 13 "Resp error ntc-h OpenCirc" 12 "Resp error meas U3 OpenCirc" 11 "Resp error meas U2 OpenCirc" 10 "Resp error meas U1 OpenCirc" 9 "Resp error meas I1 OpenCirc" 8 "Resp  error therm EMF correction" 7 "Resp error cur meas implausible" 6 "Resp error Vref" 5 "Resp error Underflow ADC ch 2" 4 "Resp error Overflow ADC ch 2" 3 "Resp error Underflow ADC ch 1" 2 "Reso error Overflow ADC ch 1" 1 "Resp error ADC interrupt" 0 "Resonse all meas errors" ;
VAL_ 1297 _81_Resp_SystemError_Item 16 "Resp error Reset EMC" 15 "Resp error Reset Watchdog" 14 "Resp error Reset illegal opcode" 13 "Resp error ADC Clock" 12 "Resp error eeprom r/w" 11 "Resp error Overcurrent detection" 10 "Resp error Configuration" 9 "Resp error System Init" 8 "Resp error System Clock" 7 "Resp error Power failure" 6 "Resp error Undertemp" 5 "Resp error Overtemp" 4 "Resp error CAN bus transmit Data" 3 "Resp error CAN bus receive Data" 2 "Resp error Parameter CRC" 1 "Resp error code CRC" 0 "Resonse all SystemErrors" ;
VAL_ 1297 _82_Resp_AllLogData_Item 42 "Resp temp minimum" 41 "Resp temp maxmimum" 40 "Resp U3 minimum" 39 "Resp U3 maximum" 38 "Resp U2 minimum" 37 "Resp U2 maxmimum" 36 "Resp U1 minimum" 35 "Resp U1 maximum" 34 "Resp current minimum" 33 "Resp current maximum" 28 "Resp oc negative activated" 27 "Resp oc positive activated" 26 "Resp run temp out spec limits" 25 "Resp run temp in spec limits" 24 "Resp run volt 3 out spec limits" 23 "Resp run volt 3 in spec limits" 22 "Resp run volt 2 out spec limits" 21 "Resp run volt 2 in spec limits" 20 "Resp run volt 1 out spec limits" 19 "Resp run volt 1 in spec limits" 18 "Resp run cur out spec limits" 17 "Resp run cur in spec limits" 16 "Resp run overall" 6 "Resp energy counter discharging" 5 "Resp energy counter charging" 4 "Resp energy counter overall" 3 "Resp Ah counter discharging" 2 "Resp Ah counter charging" 1 "Resp Ah counter overall" 0 "Response on Overall Logdata" ;
VAL_ 1297 _83_Resp_LogData_Item 42 "Resp temp minimum" 41 "Resp temp maxmimum" 40 "Resp U3 minimum" 39 "Resp U3 maximum" 38 "Resp U2 minimum" 37 "Resp U2 maxmimum" 36 "Resp U1 minimum" 35 "Resp U1 maximum" 34 "Resp current minimum" 33 "Resp current maximum" 28 "Resp oc negative activated" 27 "Resp oc positive activated" 26 "Resp run temp out spec limits" 25 "Resp run temp in spec limits" 24 "Resp run volt 3 out spec limits" 23 "Resp run volt 3 in spec limits" 22 "Resp run volt 2 out spec limits" 21 "Resp run volt 2 in spec limits" 20 "Resp run volt 1 out spec limits" 19 "Resp run volt 1 in spec limits" 18 "Resp run cur out spec limits" 17 "Resp run cur in spec limits" 16 "Resp run overall" 6 "Resp energy counter discharging" 5 "Resp energy counter charging" 4 "Resp energy counter overall" 3 "Resp Ah counter discharging" 2 "Resp Ah counter charging" 1 "Resp Ah counter overall" 0 "Response all Logdata SinceReset" ;
VAL_ 1297 _A0_Resp_TriggerMode_I 2 "CYCLIC" 1 "TRIGGERED" 0 "DISABLED" ;
VAL_ 1297 _A1_Resp_TriggerMode_U1 2 "CYCLIC" 1 "TRIGGERED" 0 "DISABLED" ;
VAL_ 1297 _A2_Resp_TriggerMode_U2 2 "CYCLIC" 1 "TRIGGERED" 0 "DISABLED" ;
VAL_ 1297 _A3_Resp_TriggerMode_U3 2 "CYCLIC" 1 "TRIGGERED" 0 "DISABLED" ;
VAL_ 1297 _A4_Resp_TriggerMode_T 2 "CYCLIC" 1 "TRIGGERED" 0 "DISABLED" ;
VAL_ 1297 _A5_Resp_TriggerMode_W 2 "CYCLIC" 1 "TRIGGERED" 0 "DISABLED" ;
VAL_ 1297 _A6_Resp_TriggerMode_As 2 "CYCLIC" 1 "TRIGGERED" 0 "DISABLED" ;
VAL_ 1297 _A7_Resp_TriggerMode_WH 2 "CYCLIC" 1 "TRIGGERED" 0 "DISABLED" ;
VAL_ 1297 _B0_Resp_Reset_Item 554 "Reset temp minimum" 553 "Reset temp maximum" 552 "Reset U3 minimum" 551 "Reset U3 maximum" 550 "Reset U2 minimum" 549 "Reset U2 maximum" 548 "Reset U1 minimum" 547 "Reset U1 maximum" 546 "Reset Current minimum" 545 "Reset Current maximum" 540 "Reset Run overcur neg activated" 539 "Reset Run overcur pos activated" 538 "Reset Run temp out spec limits" 537 "Reset Run temp in spec limits" 536 "Reset Run volt 3 out spec limits" 535 "Reset Run volt 3 in spec limits" 534 "Reset Run volt 2 out spec limits" 533 "Reset Run volt 2 in spec limits" 532 "Reset Run volt 1 out spec limits" 531 "Reset Run volt 1 in spec limits" 530 "Reset Run cur out spec limits" 529 "Reset Run cur in spec limits" 528 "Reset Runtime overall" 518 "Reset Energy counter discharging" 517 "Reset Energy counter charging" 516 "Reset Energy counter overall" 515 "Reset Ah counter discharging" 514 "Reset Ah counter charging" 513 "Reset Ah counter overall" 512 "Reset all Logdata Since Reset" 272 "Reset Reset EMC" 271 "Reset Reset Watchdog" 270 "Reset illegal opcode" 269 "Reset ADC Clock" 268 "Reset eeprom r/w" 267 "Reset overcurrent detection" 266 "Reset configuration" 265 "Reset system init" 264 "Reset system clock" 263 "Reset power failure" 262 "Reset undertemp" 261 "Reset overtemp" 260 "Reset CAN bus transmit Data" 259 "Reset CAN bus receive Data" 258 "Reset Parameter CRC" 257 "Reset Code CRC" 256 "Reset all System errors" 15 "Reset calibration data " 14 "Reset ntc-I OpenCircuit" 13 "Reset ntc-h OpenCircuit" 12 "Reset voltage measU3 OpenCircuit" 11 "Reset voltage measU2 OpenCircuit" 10 "Reset voltage measU1 OpenCircuit" 9 "Reset current measI1 OpenCircuit" 8 "Reset thermal EMF correction" 7 "Reset error current implausible" 6 "Reset error Vref" 5 "Reset error Underflow ADC ch2" 4 "Reset error Overflow ADC ch2" 3 "Reset error Underflow ADC ch1" 2 "Reset error Overflow ADC ch1" 1 "Reset error ADC interrupt" 0 "Reset all measurement errors" ;
VAL_ 1297 _B4_Resp_Actual_Mode 1 "RUN" 0 "STOP" ;
VAL_ 1297 _B4_Resp_Startup_Mode 1 "Run" 0 "Stop" ;
VAL_ 1297 _B9_Resp_Device_type 2 "IVT-S" 1 "IVT-Mod" ;
VAL_ 1297 IVT_ID_Response 255 "Resp_Cmd_Wrong_Command" 191 "Resp_Get_Set_ALIVE" 188 "Resp_Get_Set_ArtNr" 187 "Resp_Get_Set_Serialnumber" 186 "Resp_Get_Set_SW_VERSION" 185 "Resp_Get_Set_DEVICE_ID" 182 "Resp_Get_Set_THRESHOLD_NEG" 181 "Resp_Get_Set_THRESHOLD_POS" 180 "Resp_Get_Set_MODE" 179 "Resp_Get_Set_OC_TEST_TIME" 178 "Resp_Get_Set_STORE" 177 "Resp_Get_Set_TRIGGER" 176 "Resp_Get_Set_Reset_Error_Logdata" 167 "Resp_Config_Result_Wh" 166 "Resp_Config_Result_As" 165 "Resp_Config_Result_W" 164 "Resp_Config_Result_T" 163 "Resp_Config_Result_U3" 162 "Resp_Config_Result_U2" 161 "Resp_Config_Result_U1" 160 "Resp_Config_Result_I" 159 "Resp_CAN_ID_Response" 157 "Resp_CAN_ID_Command" 151 "Resp_CAN_ID_Res_Wh" 150 "Resp_CAN_ID_Res_As" 149 "Resp_CAN_ID_Res_W" 144 "Resp_CAN_ID_Res_I" 148 "Resp_CAN_ID_Res_T" 147 "Resp_CAN_ID_Res_U3" 146 "Resp_CAN_ID_Res_U2" 145 "Resp_CAN_ID_Res_U1" 131 "Resp_Error_Log_Logdata_Since_Res" 130 "Resp_Error_Log_Overall_Logdata" 129 "Resp_Error_Log_System_Error" 128 "Resp_Error_Log_Measurement_Error" ;
VAL_ 1317 IVT_ID_Result_T 4 "Vt_Result_T" ;
VAL_ 1316 IVT_ID_Result_U3 3 "Vt_Result_U3" ;
VAL_ 1315 IVT_ID_Result_U2 2 "Vt_Result_U2" ;
VAL_ 1314 IVT_ID_Result_U1 1 "Vt_Result_U1" ;
VAL_ 1313 IVT_ID_Result_I 0 "Vt_Result_I" ;
VAL_ 1041 _20_Conf_TriggerMode_I 2 "CYCLIC" 1 "TRIGGERED" 0 "DISABLED" ;
VAL_ 1041 _21_Conf_TriggerMode_U1 2 "CYCLIC" 1 "TRIGGERED" 0 "DISABLED" ;
VAL_ 1041 _22_Conf_TriggerMode_U2 2 "CYCLIC" 1 "TRIGGERED" 0 "DISABLED" ;
VAL_ 1041 _23_Conf_TriggerMode_U3 2 "CYCLIC" 1 "TRIGGERED" 0 "DISABLED" ;
VAL_ 1041 _24_Conf_TriggerMode_T 2 "CYCLIC" 1 "TRIGGERED" 0 "DISABLED" ;
VAL_ 1041 _25_Conf_TriggerMode_W 2 "CYCLIC" 1 "TRIGGERED" 0 "DISABLED" ;
VAL_ 1041 _26_Conf_TriggerMode_As 2 "CYCLIC" 1 "TRIGGERED" 0 "DISABLED" ;
VAL_ 1041 _27_Conf_TriggerMode_WH 2 "CYCLIC" 1 "TRIGGERED" 0 "DISABLED" ;
VAL_ 1041 _30_Reset_Item 554 "Reset temp minimum" 553 "Reset temp maximum" 552 "Reset U3 minimum" 551 "Reset U3 maximum" 550 "Reset U2 minimum" 549 "Reset U2 maximum" 548 "Reset U1 minimum" 547 "Reset U1 maximum" 546 "Reset Current minimum" 545 "Reset Current maximum" 540 "Reset Run overcur neg activated" 539 "Reset Run overcur pos activated" 538 "Reset Run temp out spec limits" 537 "Reset Run temp in spec limits" 536 "Reset Run volt 3 out spec limits" 535 "Reset Run volt 3 in spec limits" 534 "Reset Run volt 2 out spec limits" 533 "Reset Run volt 2 in spec limits" 532 "Reset Run volt 1 out spec limits" 531 "Reset Run volt 1 in spec limits" 530 "Reset Run cur out spec limits" 529 "Reset Run cur in spec limits" 528 "Reset Runtime overall" 518 "Reset Energy counter discharging" 517 "Reset Energy counter charging" 516 "Reset Energy counter overall" 515 "Reset Ah counter discharging" 514 "Reset Ah counter charging" 513 "Reset Ah counter overall" 512 "Reset all Logdata Since Reset" 272 "Reset Reset EMC" 271 "Reset Reset Watchdog" 270 "Reset illegal opcode" 269 "Reset ADC Clock" 268 "Reset eeprom r/w" 267 "Reset overcurrent detection" 266 "Reset configuration" 265 "Reset system init" 264 "Reset system clock" 263 "Reset power failure" 262 "Reset undertemp" 261 "Reset overtemp" 260 "Reset CAN bus transmit Data" 259 "Reset CAN bus receive Data" 258 "Reset Parameter CRC" 257 "Reset Code CRC" 256 "Reset all System errors" 15 "Reset calibration data " 14 "Reset ntc-I OpenCircuit" 13 "Reset ntc-h OpenCircuit" 12 "Reset voltage measU3 OpenCircuit" 11 "Reset voltage measU2 OpenCircuit" 10 "Reset voltage measU1 OpenCircuit" 9 "Reset current measI1 OpenCircuit" 8 "Reset thermal EMF correction" 7 "Reset error current implausible" 6 "Reset error Vref" 5 "Reset error Underflow ADC ch2" 4 "Reset error Overflow ADC ch2" 3 "Reset error Underflow ADC ch1" 2 "Reset error Overflow ADC ch1" 1 "Reset error ADC interrupt" 0 "Reset all measurement errors" ;
VAL_ 1041 _34_Actual_Mode 1 "START" 0 "STOP" ;
VAL_ 1041 _34_Startup_Mode 1 "START" 0 "STOP" ;
VAL_ 1041 _3A_RESTART_to_Bitrate 8 "250k" 4 "500k" 2 "1000k" ;
VAL_ 1041 _40_Get_MeasError_Item 15 "Get error calibration data" 14 "Get error ntc-I OpenCirc." 13 "Get error ntc-h OpenCirc." 12 "Get error volt meas U3 OpenCirc." 11 "Get error volt meas U2 OpenCirc." 10 "Get error volt meas U1 OpenCirc." 9 "Get error cur meas I1 OpenCirc." 8 "Get error thermal EMF correction" 7 "Get error cur meas implausible" 6 "Get error Vref" 5 "Get error Underflow ADC ch 2" 4 "Get error Overflow ADC ch 2" 3 "Get error Underflow ADC ch 1" 2 "Get error Overflow ADC ch 1" 1 "Get error ADC interrupt" 0 "Get all meas Errors" ;
VAL_ 1041 _41_Get_SystemError_Item 16 "Get error reset EMC" 15 "Get error reset Watchdog" 14 "Get error reset illegal opcode" 13 "Get error ADC clock" 12 "Get error eeprom r/w" 11 "Get error overcurrent detection" 10 "Get error configuration" 9 "Get error system init" 8 "Get error system clock" 7 "Get error power failure" 6 "Get error undertemp" 5 "Get error overtemp" 4 "Get error CAN bus transmit Data" 3 "Get error CAN  bus receive Data" 2 "Get error Code Parameter CRC" 1 "Get error Code CRC" 0 "Get all System errors" ;
VAL_ 1041 _42_Get_AllLogData_Item 42 "Get Temperature minimum" 41 "Get Temperature maximum" 40 "Get U3 minimum" 39 "Get U3 maxmimum " 38 "Get U2 minimum" 37 "Get U2 maximum" 36 "Get U1 minimum" 35 "Get U1 maxmimum" 34 "Get current minimum" 33 "Get current maximum" 28 "Get run overcur neg activated" 27 "Get run overcur pos activated" 26 "Get run temp out spec limits" 25 "Get run temp in spec limits" 24 "Get run volt2 out spec limits" 23 "Get run volt3 in spec limits" 22 "Get run volt2 out spec limits" 21 "Get run volt2 in spec limits" 20 "Get run volt1 out spec limits" 19 "Get run volt1 in spec limits" 18 "Get run cur out spec limits" 17 "Get Run cur in spec limits" 16 "Get Runtime overall" 6 "Get Energy counter discharging" 5 "Get Energy counter charging" 4 "Get Energy counter overall" 3 "Get Ah counter discharging" 2 "Get Ah counter charging" 1 "Get Ah counter overall" 0 "Get Overall Logdata" ;
VAL_ 1041 _43_Get_LogData_Item 42 "Get Temperature minimum" 41 "Get Temperature maximum" 40 "Get U3 minimum" 39 "Get U3 maxmimum " 38 "Get U2 minimum" 37 "Get U2 maximum" 36 "Get U1 minimum" 35 "Get U1 maxmimum" 34 "Get current minimum" 33 "Get current maximum" 28 "Get run overcur neg activated" 27 "Get run overcur pos activated" 26 "Get run temp out spec limits" 25 "Get run temp in spec limits" 24 "Get run volt2 out spec limits" 23 "Get run volt3 in spec limits" 22 "Get run volt2 out spec limits" 21 "Get run volt2 in spec limits" 20 "Get run volt1 out spec limits" 19 "Get run volt1 in spec limits" 18 "Get run cur out spec limits" 17 "Get Run cur in spec limits" 16 "Get Runtime overall" 6 "Get Energy counter discharging" 5 "Get Energy counter charging" 4 "Get Energy counter overall" 3 "Get Ah counter discharging" 2 "Get Ah counter charging" 1 "Get Ah counter overall" 0 "Get Overall Logdata" ;
VAL_ 1041 IVT_ID_Cmd 124 "Get_cmd_and_info_ArtNr" 123 "Get_cmd_and_info_SN" 122 "Get_cmd_and_info_SW_Version" 121 "Get_cmd_and_info_DEVICE_ID" 118 "Get_cmd_and_info_THRESHOLD_NEG" 117 "Get_cmd_and_info_THRESHOLD_POS" 116 "Get_cmd_and_info_MODE" 115 "Get_cmd_and_info_OC_TEST_TIME" 103 "Get_Config_Res_Wh" 102 "Get_Config_Res_As" 101 "Get_Config_Res_W" 100 "Get_Config_Res_T" 99 "Get_Config_Res_U3" 98 "Get_Config_Res_U2" 97 "Get_Config_Res_U1" 96 "Get_Config_Res_I" 95 "Get_CAN_ID_Response" 93 "Get_CAN_ID_Command" 87 "Get_CAN_ID_Res_Wh" 86 "Get_CAN_ID_Res_As" 85 "Get_CAN_ID_Res_W" 84 "Get_CAN_ID_Res_T" 83 "Get_CAN_ID_Res_U3" 82 "Get_CAN_ID_Res_U2" 81 "Get_CAN_ID_Res_U1" 80 "Get_CAN_ID_Res_I" 67 "Get_Logdata_Since_Reset" 66 "Get_Overall_Logdata" 65 "Get_System_Errors" 64 "Get_Measurement_Errors" 63 "Set_RESTART" 61 "Set_RESTART_to_default" 58 "RESTART_to_Bitrate" 54 "Set_THRESHOLD_neg" 53 "Set_THRESHOLD_pos" 32 "Set_MODE_Result_I" 16 "Set_CAN_ID_Result_I" 52 "Set_MODE" 51 "START_OC_TEST" 50 "STORE" 49 "TRIGGER" 48 "Reset_Err_Log" 39 "Set_MODE_Result_Wh" 38 "Set_MODE_Result_As" 37 "Set_MODE_Result_W" 23 "Set_CAN_ID_Result_Wh" 22 "Set_CAN_ID_Result_As" 21 "Set_CAN_ID_Result_W" 20 "Set_CAN_ID_Result_T" 35 "Set_MODE_Result_U3" 31 "Set_CAN_ID_Response" 29 "Set_CAN_ID_Cmd" 19 "Set_CAN_ID_Result_U3" 18 "Set_CAN_ID_Result_U2" 36 "Set_MODE_Result_T" 34 "Set_MODE_Result_U2" 33 "Set_MODE_Result_U1" 17 "Set_CAN_ID_Result_U1" ;
SIG_VALTYPE_ 3221225472 VCU_GNSS_v_x : 1;
SIG_VALTYPE_ 3221225472 VCU_GNSS_v_y : 1;
SIG_VALTYPE_ 3221225472 VCU_GNSS_v_z : 1;
SIG_VALTYPE_ 600 VCU_IMU_acc_x : 1;
SIG_VALTYPE_ 600 VCU_IMU_ang_x : 1;
SIG_VALTYPE_ 601 VCU_IMU_acc_y : 1;
SIG_VALTYPE_ 601 VCU_IMU_ang_y : 1;
SIG_VALTYPE_ 602 VCU_IMU_acc_z : 1;
SIG_VALTYPE_ 602 VCU_IMU_ang_z : 1;
SIG_VALTYPE_ 2047 VCU_dbg1 : 1;
SIG_VALTYPE_ 2047 VCU_dbg2 : 1;
